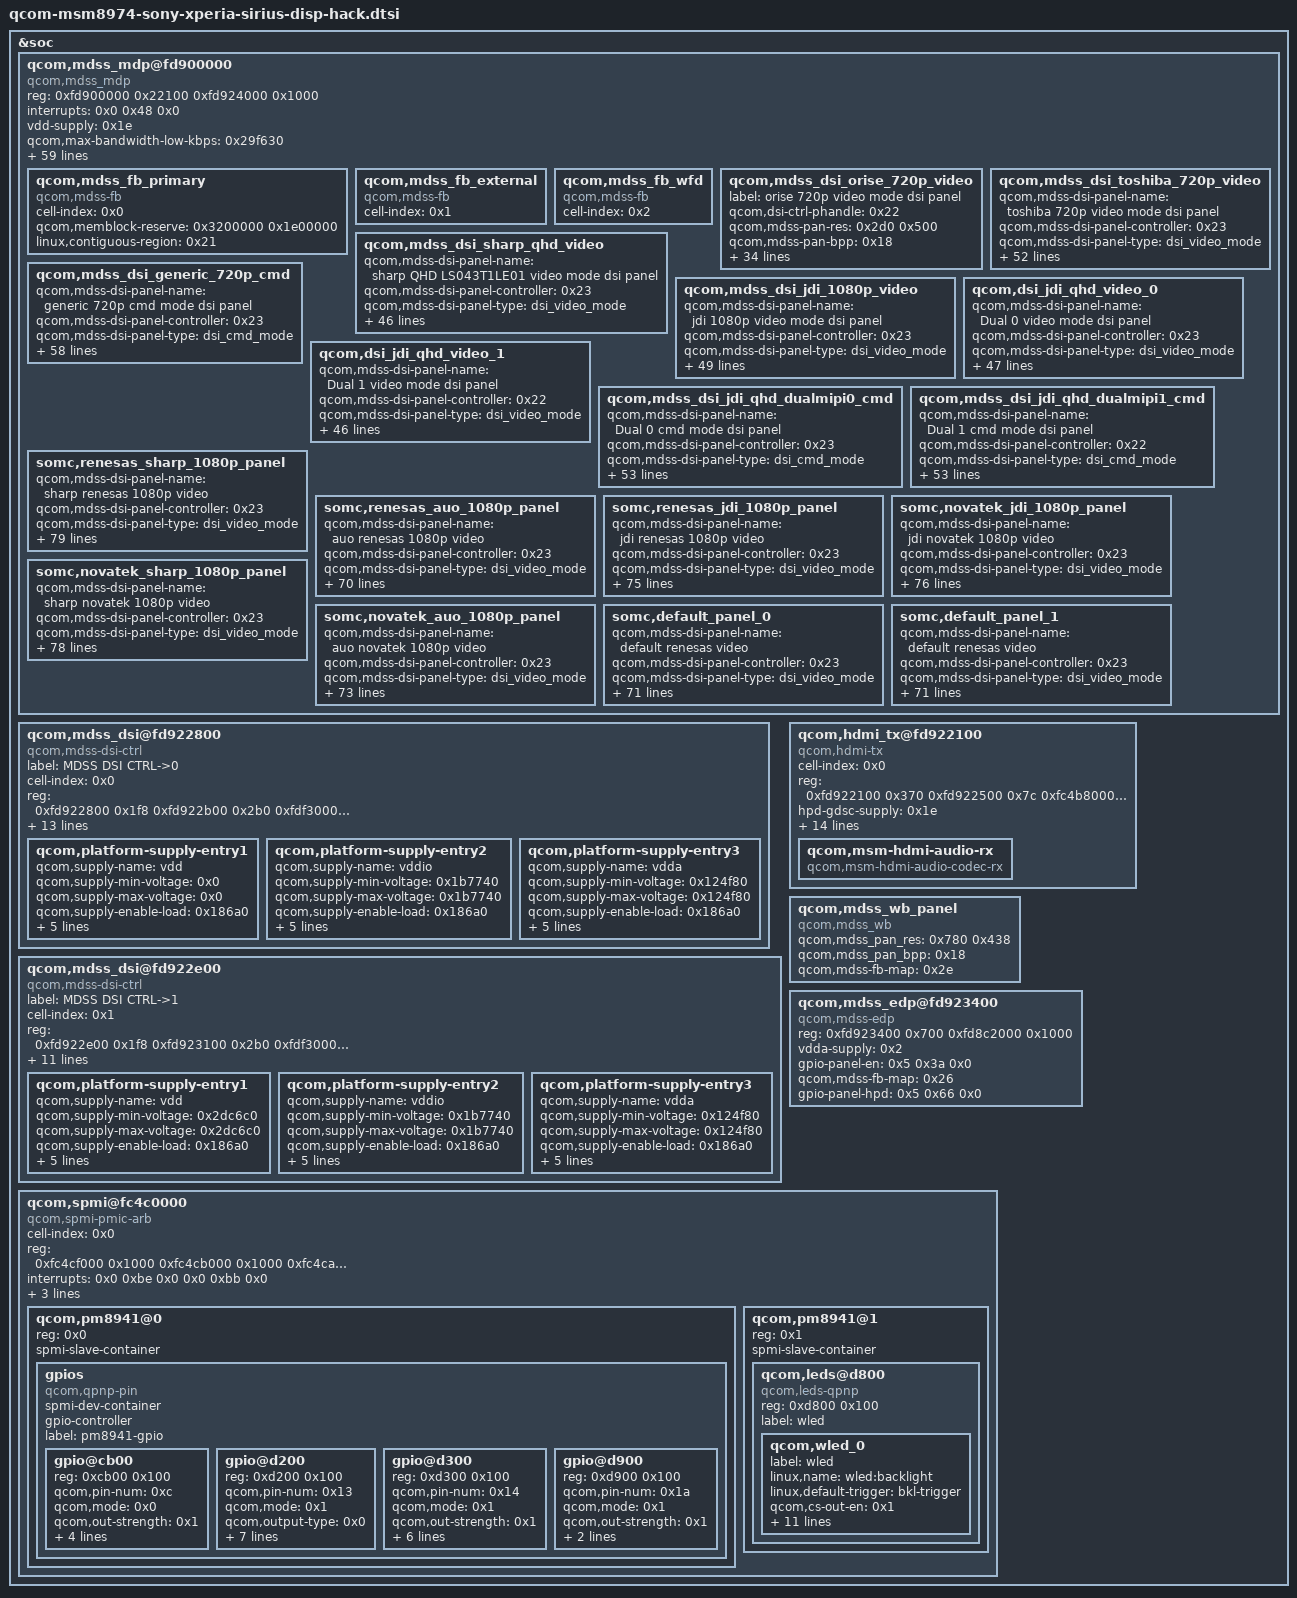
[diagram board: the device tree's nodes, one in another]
&soc {
		qcom,mdss_mdp@fd900000 {
			compatible = "qcom,mdss_mdp";
			reg = <0xfd900000 0x22100 0xfd924000 0x1000>;
			reg-names = "mdp_phys", "vbif_phys";
			interrupts = <0x0 0x48 0x0>;
			vdd-supply = <0x1e>;
			qcom,max-bandwidth-low-kbps = <0x29f630>;
			qcom,max-bandwidth-high-kbps = <0x2dc6c0>;
			qcom,msm-bus,name = "mdss_mdp";
			qcom,msm-bus,num-cases = <0x3>;
			qcom,msm-bus,num-paths = <0x1>;
			qcom,msm-bus,vectors-KBps = <0x16 0x200 0x0 0x0 0x16 0x200 0x0 0x61a800 0x16 0x200 0x0 0x61a800>;
			qcom,mdss-ab-factor = <0x2 0x1>;
			qcom,mdss-ib-factor = <0x13 0xa>;
			qcom,mdss-clk-factor = <0x5 0x4>;
			qcom,mdss-ib-factor-overlap = <0x7 0x4>;
			qcom,max-clk-rate = <0x1312d000>;
			qcom,mdss-pipe-vig-off = <0x1200 0x1600 0x1a00>;
			qcom,mdss-pipe-rgb-off = <0x1e00 0x2200 0x2600>;
			qcom,mdss-pipe-dma-off = <0x2a00 0x2e00>;
			qcom,mdss-pipe-vig-fetch-id = <0x1 0x4 0x7>;
			qcom,mdss-pipe-rgb-fetch-id = <0x10 0x11 0x12>;
			qcom,mdss-pipe-dma-fetch-id = <0xa 0xd>;
			qcom,mdss-pipe-vig-xin-id = <0x0 0x4 0x8>;
			qcom,mdss-pipe-rgb-xin-id = <0x1 0x5 0x9>;
			qcom,mdss-pipe-dma-xin-id = <0x2 0xa>;
			qcom,mdss-pipe-vig-clk-ctrl-offsets = <0x3ac 0x0 0x0 0x3b4 0x0 0x0 0x3bc 0x0 0x0>;
			qcom,mdss-pipe-rgb-clk-ctrl-offsets = <0x3ac 0x4 0x8 0x3b4 0x4 0x8 0x3bc 0x4 0x8>;
			qcom,mdss-pipe-dma-clk-ctrl-offsets = <0x3ac 0x8 0xc 0x3b4 0x8 0xc>;
			qcom,mdss-smp-data = <0x16 0x1000>;
			qcom,mdss-ctl-off = <0x600 0x700 0x800 0x900 0xa00>;
			qcom,mdss-mixer-intf-off = <0x3200 0x3600 0x3a00>;
			qcom,mdss-mixer-wb-off = <0x3e00 0x4200>;
			qcom,mdss-dspp-off = <0x4600 0x4a00 0x4e00>;
			qcom,mdss-wb-off = <0x11100 0x11500 0x11900 0x11d00 0x12100>;
			qcom,mdss-intf-off = <0x12500 0x12700 0x12900 0x12b00>;
			qcom,mdss-has-wfd-blk;
			qcom,vbif-settings = <0x4 0x1>;
			qcom,mdp-settings = <0x2e0 0xe9 0x2e4 0x55 0x3ac 0xc0000ccc 0x3b4 0xc0000ccc 0x3bc 0xcccccc 0x4a8 0xcccc0c0 0x4b0 0xccccc0c0 0x4b8 0xccccc000>;
			qcom,mdss-prefill-outstanding-buffer-bytes = <0x400>;
			qcom,mdss-prefill-y-buffer-bytes = <0x1000>;
			qcom,mdss-prefill-scaler-buffer-lines-bilinear = <0x2>;
			qcom,mdss-prefill-scaler-buffer-lines-caf = <0x4>;
			qcom,mdss-prefill-post-scaler-buffer-pixels = <0x0>;
			qcom,mdss-prefill-pingpong-buffer-pixels = <0x1000>;
			qcom,mdss-prefill-fbc-lines = <0x2>;
			qcom,mdss-pingpong-off = <0x12d00 0x12e00 0x12f00>;
			qcom,mdss-has-bwc;
			qcom,mdss-has-decimation;
			qcom,mdss-ad-off = <0x13100 0x13300>;
			vdd-cx-supply = <0x1f>;
			qcom,mdss-pref-prim-intf = "dsi";
			batfet-supply = <0x20>;
			linux,phandle = <0x27>;
			phandle = <0x27>;

			qcom,mdss_fb_primary {
				cell-index = <0x0>;
				compatible = "qcom,mdss-fb";
				qcom,memblock-reserve = <0x3200000 0x1e00000>;
				linux,contiguous-region = <0x21>;
				linux,phandle = <0x26>;
				phandle = <0x26>;
			};

			qcom,mdss_fb_external {
				cell-index = <0x1>;
				compatible = "qcom,mdss-fb";
				linux,phandle = <0x2d>;
				phandle = <0x2d>;
			};

			qcom,mdss_fb_wfd {
				cell-index = <0x2>;
				compatible = "qcom,mdss-fb";
				linux,phandle = <0x2e>;
				phandle = <0x2e>;
			};

			qcom,mdss_dsi_orise_720p_video {
				label = "orise 720p video mode dsi panel";
				qcom,dsi-ctrl-phandle = <0x22>;
				qcom,mdss-pan-res = <0x2d0 0x500>;
				qcom,mdss-pan-bpp = <0x18>;
				qcom,mdss-pan-dest = "display_2";
				qcom,mdss-pan-porch-values = <0x20 0xc 0x90 0x3 0x4 0x9>;
				qcom,mdss-pan-underflow-clr = <0xff>;
				qcom,mdss-pan-bl-levels = <0x1 0xff>;
				qcom,mdss-pan-dsi-mode = <0x0>;
				qcom,mdss-pan-dsi-h-pulse-mode = <0x0>;
				qcom,mdss-pan-dsi-h-power-stop = <0x0 0x0 0x0>;
				qcom,mdss-pan-dsi-bllp-power-stop = <0x1 0x1>;
				qcom,mdss-pan-dsi-traffic-mode = <0x1>;
				qcom,mdss-pan-dsi-dst-format = <0x3>;
				qcom,mdss-pan-dsi-vc = <0x0>;
				qcom,mdss-pan-dsi-rgb-swap = <0x0>;
				qcom,mdss-pan-dsi-data-lanes = <0x1 0x1 0x1 0x1>;
				qcom,mdss-pan-dsi-dlane-swap = <0x0>;
				qcom,mdss-pan-dsi-t-clk = <0x1b 0x4>;
				qcom,mdss-pan-dsi-stream = <0x0>;
				qcom,mdss-pan-dsi-mdp-tr = <0x0>;
				qcom,mdss-pan-dsi-dma-tr = <0x4>;
				qcom,mdss-pan-dsi-framerate = <0x3c>;
				qcom,panel-phy-regulatorSettings = [03 01 01 00 20 00 01];
				qcom,panel-phy-timingSettings = <0x69291f00 0x5555192a 0x2a030400>;
				qcom,panel-phy-strengthCtrl = [77 06];
				qcom,panel-phy-bistCtrl = [00 00 b1 ff 00 00];
				qcom,panel-phy-laneConfig = [00 c2 45 00 00 00 00 01 75 00 c2 45 00 00 00 00 01 75 00 c2 45 00 00 00 00 01 75 00 c2 45 00 00 00 00 01 75 00 02 45 00 00 00 00 01 97];
				qcom,panel-on-cmds = [05 01 00 00 78 00 02 11 00 05 01 00 00 78 00 02 29 00];
				qcom,on-cmds-dsi-state = "DSI_LP_MODE";
				qcom,panel-off-cmds = [05 01 00 00 32 00 02 28 00 05 01 00 00 78 00 02 10 00];
				qcom,off-cmds-dsi-state = "DSI_LP_MODE";
			};

			qcom,mdss_dsi_toshiba_720p_video {
				qcom,mdss-dsi-panel-name = "toshiba 720p video mode dsi panel";
				qcom,mdss-dsi-panel-controller = <0x23>;
				qcom,mdss-dsi-panel-type = "dsi_video_mode";
				qcom,mdss-dsi-panel-destination = "display_1";
				qcom,mdss-dsi-panel-framerate = <0x3c>;
				qcom,mdss-dsi-virtual-channel-id = <0x0>;
				qcom,mdss-dsi-stream = <0x0>;
				qcom,mdss-dsi-panel-width = <0x2d0>;
				qcom,mdss-dsi-panel-height = <0x500>;
				qcom,mdss-dsi-h-front-porch = <0x90>;
				qcom,mdss-dsi-h-back-porch = <0x20>;
				qcom,mdss-dsi-h-pulse-width = <0xc>;
				qcom,mdss-dsi-h-sync-skew = <0x0>;
				qcom,mdss-dsi-v-back-porch = <0x3>;
				qcom,mdss-dsi-v-front-porch = <0x9>;
				qcom,mdss-dsi-v-pulse-width = <0x4>;
				qcom,mdss-dsi-h-left-border = <0x0>;
				qcom,mdss-dsi-h-right-border = <0x0>;
				qcom,mdss-dsi-v-top-border = <0x0>;
				qcom,mdss-dsi-v-bottom-border = <0x0>;
				qcom,mdss-dsi-bpp = <0x18>;
				qcom,mdss-dsi-underflow-color = <0xff>;
				qcom,mdss-dsi-border-color = <0x0>;
				qcom,mdss-dsi-on-command = [23 01 00 00 0a 00 02 b0 00 23 01 00 00 0a 00 02 b2 00 23 01 00 00 0a 00 02 b3 0c 23 01 00 00 0a 00 02 b4 02 29 01 00 00 00 00 06 c0 40 02 7f c8 08 29 01 00 00 00 00 10 c1 00 a8 00 00 00 00 00 9d 08 27 00 00 00 00 00 29 01 00 00 00 00 06 c2 00 00 09 00 00 23 01 00 00 0a 00 02 c3 04 29 01 00 00 00 00 04 c4 4d 83 00 29 01 00 00 00 00 0b c6 12 00 08 71 00 00 00 80 00 04 23 01 00 00 0a 00 02 c7 22 29 01 00 00 00 00 05 c8 4c 0c 0c 0c 29 01 00 00 00 00 0e c9 00 40 00 16 32 2e 3a 43 3e 3c 45 79 3f 29 01 00 00 00 00 0e ca 00 46 1a 23 21 1c 25 31 2d 49 5f 7f 3f 29 01 00 00 00 00 0e cb 00 4c 20 3a 42 40 47 4b 42 3e 46 7e 3f 29 01 00 00 00 00 0e cc 00 41 19 21 1d 14 18 1f 1d 25 3f 73 3f 29 01 00 00 00 00 0e cd 23 79 5a 5f 57 4c 51 51 45 3f 4b 7f 3f 29 01 00 00 00 00 0e ce 00 40 14 20 1a 0e 0e 13 08 00 05 46 1c 29 01 00 00 00 00 04 d0 6a 64 01 29 01 00 00 00 00 03 d1 77 d4 23 01 00 00 0a 00 02 d3 33 29 01 00 00 00 00 03 d5 0f 0f 29 01 00 00 00 00 07 d8 34 64 23 25 62 32 29 01 00 00 00 00 0c de 10 7b 11 0a 00 00 00 00 00 00 00 29 01 00 00 00 00 09 fd 04 55 53 00 70 ff 10 73 23 01 00 00 0a 00 02 e2 00 05 01 00 00 78 00 02 11 00 05 01 00 00 32 00 02 29 00];
				qcom,mdss-dsi-off-command = [05 01 00 00 32 00 02 28 00 05 01 00 00 78 00 02 10 00];
				qcom,mdss-dsi-on-command-state = "dsi_lp_mode";
				qcom,mdss-dsi-off-command-state = "dsi_hs_mode";
				qcom,mdss-dsi-h-sync-pulse = <0x0>;
				qcom,mdss-dsi-traffic-mode = "non_burst_sync_event";
				qcom,mdss-dsi-bllp-eof-power-mode;
				qcom,mdss-dsi-bllp-power-mode;
				qcom,mdss-dsi-lane-0-state;
				qcom,mdss-dsi-lane-1-state;
				qcom,mdss-dsi-lane-2-state;
				qcom,mdss-dsi-lane-3-state;
				qcom,mdss-dsi-panel-timings = <0xb0231b00 0x94931e25 0x15030400>;
				qcom,mdss-dsi-t-clk-post = <0x4>;
				qcom,mdss-dsi-t-clk-pre = <0x1b>;
				qcom,mdss-dsi-bl-min-level = <0x1>;
				qcom,mdss-dsi-bl-max-level = <0xfff>;
				qcom,mdss-dsi-dma-trigger = "trigger_sw";
				qcom,mdss-dsi-mdp-trigger = "none";
				qcom,mdss-dsi-bl-pmic-control-type = "bl_ctrl_wled";
				qcom,mdss-dsi-pan-enable-dynamic-fps;
				qcom,mdss-dsi-pan-fps-update = "dfps_immediate_porch_mode";
				qcom,mdss-dsi-min-refresh-rate = <0x2d>;
				qcom,mdss-dsi-reset-sequence = <0x1 0x14 0x0 0xc8 0x1 0x14>;
				qcom,cont-splash-enabled;
			};

			qcom,mdss_dsi_sharp_qhd_video {
				qcom,mdss-dsi-panel-name = "sharp QHD LS043T1LE01 video mode dsi panel";
				qcom,mdss-dsi-panel-controller = <0x23>;
				qcom,mdss-dsi-panel-type = "dsi_video_mode";
				qcom,mdss-dsi-panel-destination = "display_1";
				qcom,mdss-dsi-panel-framerate = <0x3c>;
				qcom,mdss-dsi-virtual-channel-id = <0x0>;
				qcom,mdss-dsi-stream = <0x0>;
				qcom,mdss-dsi-panel-width = <0x21c>;
				qcom,mdss-dsi-panel-height = <0x3c0>;
				qcom,mdss-dsi-h-front-porch = <0x30>;
				qcom,mdss-dsi-h-back-porch = <0x50>;
				qcom,mdss-dsi-h-pulse-width = <0x20>;
				qcom,mdss-dsi-h-sync-skew = <0x0>;
				qcom,mdss-dsi-v-back-porch = <0xf>;
				qcom,mdss-dsi-v-front-porch = <0x3>;
				qcom,mdss-dsi-v-pulse-width = <0xa>;
				qcom,mdss-dsi-h-left-border = <0x0>;
				qcom,mdss-dsi-h-right-border = <0x0>;
				qcom,mdss-dsi-v-top-border = <0x0>;
				qcom,mdss-dsi-v-bottom-border = <0x0>;
				qcom,mdss-dsi-bpp = <0x18>;
				qcom,mdss-dsi-color-order = "rgb_swap_bgr";
				qcom,mdss-dsi-underflow-color = <0xff>;
				qcom,mdss-dsi-border-color = <0x0>;
				qcom,mdss-dsi-on-command = [05 01 00 00 32 00 02 01 00 05 01 00 00 0a 00 02 11 00 15 01 00 00 0a 00 02 53 2c 15 01 00 00 0a 00 02 51 ff 05 01 00 00 0a 00 02 29 00 15 01 00 00 0a 00 02 ae 03 15 01 00 00 0a 00 02 3a 77];
				qcom,mdss-dsi-off-command = [05 01 00 00 0a 00 02 28 00 05 01 00 00 78 00 02 10 00];
				qcom,mdss-dsi-on-command-state = "dsi_lp_mode";
				qcom,mdss-dsi-off-command-state = "dsi_hs_mode";
				qcom,mdss-dsi-h-sync-pulse = <0x1>;
				qcom,mdss-dsi-traffic-mode = "non_burst_sync_pulse";
				qcom,mdss-dsi-bllp-eof-power-mode;
				qcom,mdss-dsi-bllp-power-mode;
				qcom,mdss-dsi-lane-0-state;
				qcom,mdss-dsi-lane-1-state;
				qcom,mdss-dsi-panel-timings = <0x461d2000 0x393a2121 0x32030400>;
				qcom,mdss-dsi-t-clk-post = <0x4>;
				qcom,mdss-dsi-t-clk-pre = <0x1c>;
				qcom,mdss-dsi-bl-min-level = <0x1>;
				qcom,mdss-dsi-bl-max-level = <0xfff>;
				qcom,mdss-dsi-dma-trigger = "trigger_sw";
				qcom,mdss-dsi-mdp-trigger = "trigger_sw";
				qcom,mdss-dsi-bl-pmic-control-type = "bl_ctrl_wled";
				qcom,mdss-dsi-reset-sequence = <0x1 0x14 0x0 0xc8 0x1 0x14>;
			};

			qcom,mdss_dsi_generic_720p_cmd {
				qcom,mdss-dsi-panel-name = "generic 720p cmd mode dsi panel";
				qcom,mdss-dsi-panel-controller = <0x23>;
				qcom,mdss-dsi-panel-type = "dsi_cmd_mode";
				qcom,mdss-dsi-panel-destination = "display_1";
				qcom,mdss-dsi-panel-framerate = <0x3c>;
				qcom,mdss-dsi-stream = <0x0>;
				qcom,mdss-dsi-panel-width = <0x300>;
				qcom,mdss-dsi-panel-height = <0x500>;
				qcom,mdss-dsi-h-front-porch = <0x1a>;
				qcom,mdss-dsi-h-back-porch = <0x1a>;
				qcom,mdss-dsi-h-pulse-width = <0x1a>;
				qcom,mdss-dsi-h-sync-skew = <0x0>;
				qcom,mdss-dsi-v-back-porch = <0x2>;
				qcom,mdss-dsi-v-front-porch = <0x2>;
				qcom,mdss-dsi-v-pulse-width = <0x2>;
				qcom,mdss-dsi-h-left-border = <0x0>;
				qcom,mdss-dsi-h-right-border = <0x0>;
				qcom,mdss-dsi-v-top-border = <0x0>;
				qcom,mdss-dsi-v-bottom-border = <0x0>;
				qcom,mdss-dsi-bpp = <0x18>;
				qcom,mdss-dsi-underflow-color = <0xff>;
				qcom,mdss-dsi-border-color = <0x0>;
				qcom,mdss-dsi-on-command = [05 01 00 00 78 00 01 11 15 01 00 00 0a 00 02 36 00 05 01 00 00 0a 00 01 29 15 01 00 00 0a 00 02 53 24 15 01 00 00 0a 00 02 35 00];
				qcom,mdss-dsi-off-command = [05 01 00 00 0a 00 01 34 05 01 00 00 78 00 01 10 05 01 00 00 78 00 01 28 15 01 00 00 0a 00 02 53 00];
				qcom,mdss-dsi-on-command-state = "dsi_lp_mode";
				qcom,mdss-dsi-off-command-state = "dsi_hs_mode";
				qcom,mdss-dsi-h-sync-pulse = <0x0>;
				qcom,mdss-dsi-traffic-mode = "non_burst_sync_event";
				qcom,mdss-dsi-bllp-eof-power-mode;
				qcom,mdss-dsi-bllp-power-mode;
				qcom,mdss-dsi-lane-0-state;
				qcom,mdss-dsi-lane-1-state;
				qcom,mdss-dsi-lane-2-state;
				qcom,mdss-dsi-lane-3-state;
				qcom,mdss-dsi-te-pin-select = <0x1>;
				qcom,mdss-dsi-wr-mem-start = <0x2c>;
				qcom,mdss-dsi-wr-mem-continue = <0x3c>;
				qcom,mdss-dsi-te-dcs-command = <0x1>;
				qcom,mdss-dsi-te-check-enable;
				qcom,mdss-dsi-te-using-te-pin;
				qcom,mdss-dsi-panel-timings = <0x6e261b00 0x35342028 0x17030400>;
				qcom,mdss-dsi-t-clk-post = <0x20>;
				qcom,mdss-dsi-t-clk-pre = <0x2a>;
				qcom,mdss-dsi-bl-min-level = <0x1>;
				qcom,mdss-dsi-bl-max-level = <0xff>;
				qcom,mdss-dsi-bl-pmic-pwm-frequency = <0x64>;
				qcom,mdss-dsi-bl-pmic-bank-select = <0x7>;
				qcom,mdss-dsi-dma-trigger = "trigger_sw";
				qcom,mdss-dsi-mdp-trigger = "none";
				qcom,mdss-dsi-bl-pmic-control-type = "bl_ctrl_pwm";
				qcom,mdss-dsi-reset-sequence = <0x1 0x14 0x0 0xc8 0x1 0x14>;
				qcom,panel-roi-alignment = <0x2 0x2 0x2 0x2 0x0 0x0>;
				qcom,partial-update-enabled;
				qcom,cont-splash-enabled;
			};

			qcom,mdss_dsi_jdi_1080p_video {
				qcom,mdss-dsi-panel-name = "jdi 1080p video mode dsi panel";
				qcom,mdss-dsi-panel-controller = <0x23>;
				qcom,mdss-dsi-panel-type = "dsi_video_mode";
				qcom,mdss-dsi-panel-destination = "display_1";
				qcom,mdss-dsi-panel-framerate = <0x3c>;
				qcom,mdss-dsi-virtual-channel-id = <0x0>;
				qcom,mdss-dsi-stream = <0x0>;
				qcom,mdss-dsi-panel-width = <0x438>;
				qcom,mdss-dsi-panel-height = <0x780>;
				qcom,mdss-dsi-h-front-porch = <0x60>;
				qcom,mdss-dsi-h-back-porch = <0x40>;
				qcom,mdss-dsi-h-pulse-width = <0x10>;
				qcom,mdss-dsi-h-sync-skew = <0x0>;
				qcom,mdss-dsi-v-back-porch = <0x10>;
				qcom,mdss-dsi-v-front-porch = <0x4>;
				qcom,mdss-dsi-v-pulse-width = <0x1>;
				qcom,mdss-dsi-h-left-border = <0x0>;
				qcom,mdss-dsi-h-right-border = <0x0>;
				qcom,mdss-dsi-v-top-border = <0x0>;
				qcom,mdss-dsi-v-bottom-border = <0x0>;
				qcom,mdss-dsi-bpp = <0x18>;
				qcom,mdss-dsi-underflow-color = <0xff>;
				qcom,mdss-dsi-border-color = <0x0>;
				qcom,mdss-dsi-on-command = [15 01 00 00 00 00 02 55 00 15 01 00 00 00 00 02 53 2c 15 01 00 00 00 00 02 35 00 05 01 00 00 78 00 02 29 00 05 01 00 00 78 00 02 11 00];
				qcom,mdss-dsi-off-command = [05 01 00 00 02 00 02 28 00 05 01 00 00 79 00 02 10 00];
				qcom,mdss-dsi-on-command-state = "dsi_lp_mode";
				qcom,mdss-dsi-off-command-state = "dsi_hs_mode";
				qcom,mdss-dsi-h-sync-pulse = <0x0>;
				qcom,mdss-dsi-traffic-mode = "burst_mode";
				qcom,mdss-dsi-bllp-eof-power-mode;
				qcom,mdss-dsi-bllp-power-mode;
				qcom,mdss-dsi-lane-0-state;
				qcom,mdss-dsi-lane-1-state;
				qcom,mdss-dsi-lane-2-state;
				qcom,mdss-dsi-lane-3-state;
				qcom,mdss-dsi-panel-timings = <0xe7362400 0x666a2a3a 0x2d030400>;
				qcom,mdss-dsi-t-clk-post = <0x4>;
				qcom,mdss-dsi-t-clk-pre = <0x1b>;
				qcom,mdss-dsi-bl-min-level = <0x1>;
				qcom,mdss-dsi-bl-max-level = <0xfff>;
				qcom,mdss-dsi-dma-trigger = "trigger_sw";
				qcom,mdss-dsi-mdp-trigger = "none";
				qcom,mdss-dsi-bl-pmic-control-type = "bl_ctrl_wled";
				qcom,mdss-dsi-reset-sequence = <0x1 0x14 0x0 0xc8 0x1 0x14>;
				qcom,mdss-pan-physical-width-dimension = <0x3d>;
				qcom,mdss-pan-physical-height-dimension = <0x6e>;
				qcom,cont-splash-enabled;
			};

			qcom,dsi_jdi_qhd_video_0 {
				qcom,mdss-dsi-panel-name = "Dual 0 video mode dsi panel";
				qcom,mdss-dsi-panel-controller = <0x23>;
				qcom,mdss-dsi-panel-type = "dsi_video_mode";
				qcom,mdss-dsi-panel-destination = "display_1";
				qcom,mdss-dsi-panel-framerate = <0x3c>;
				qcom,mdss-dsi-virtual-channel-id = <0x0>;
				qcom,mdss-dsi-stream = <0x0>;
				qcom,mdss-dsi-panel-width = <0x500>;
				qcom,mdss-dsi-panel-height = <0x5a0>;
				qcom,mdss-dsi-h-front-porch = <0x78>;
				qcom,mdss-dsi-h-back-porch = <0x2c>;
				qcom,mdss-dsi-h-pulse-width = <0x10>;
				qcom,mdss-dsi-h-sync-skew = <0x0>;
				qcom,mdss-dsi-v-back-porch = <0x4>;
				qcom,mdss-dsi-v-front-porch = <0x8>;
				qcom,mdss-dsi-v-pulse-width = <0x4>;
				qcom,mdss-dsi-h-left-border = <0x0>;
				qcom,mdss-dsi-h-right-border = <0x0>;
				qcom,mdss-dsi-v-top-border = <0x0>;
				qcom,mdss-dsi-v-bottom-border = <0x0>;
				qcom,mdss-dsi-bpp = <0x18>;
				qcom,mdss-dsi-underflow-color = <0xff>;
				qcom,mdss-dsi-border-color = <0x0>;
				qcom,mdss-dsi-h-sync-pulse = <0x0>;
				qcom,mdss-dsi-traffic-mode = "non_burst_sync_event";
				qcom,mdss-dsi-bllp-eof-power-mode;
				qcom,mdss-dsi-bllp-power-mode;
				qcom,mdss-dsi-panel-broadcast-mode;
				qcom,mdss-dsi-lane-0-state;
				qcom,mdss-dsi-lane-1-state;
				qcom,mdss-dsi-lane-2-state;
				qcom,mdss-dsi-lane-3-state;
				qcom,mdss-dsi-panel-timings = <0xcd322200 0x60642634 0x29030400>;
				qcom,mdss-dsi-t-clk-post = <0x3>;
				qcom,mdss-dsi-t-clk-pre = <0x27>;
				qcom,mdss-dsi-bl-max-level = <0xfff>;
				qcom,mdss-dsi-dma-trigger = "trigger_sw";
				qcom,mdss-dsi-mdp-trigger = "none";
				qcom,mdss-dsi-bl-pmic-control-type = "bl_ctrl_pwm";
				qcom,mdss-dsi-on-command = [05 01 00 00 0a 00 01 00 15 01 00 00 0a 00 02 3a 77 39 01 00 00 0a 00 05 2a 00 00 04 ff 39 01 00 00 0a 00 05 2b 00 00 05 9f 15 01 00 00 0a 00 02 35 00 39 01 00 00 0a 00 03 44 00 00 15 01 00 00 0a 00 02 51 ff 15 01 00 00 0a 00 02 53 24 15 01 00 00 0a 00 02 55 00 05 01 00 00 78 00 01 11 23 01 00 00 0a 00 02 b0 00 29 01 00 00 0a 00 02 b3 14 29 01 00 00 0a 00 14 ce 7d 40 48 56 67 78 88 98 a7 b5 c3 d1 de e9 f2 fa ff 04 00 23 01 00 00 0a 00 02 b0 03 05 01 00 00 10 00 01 29];
				qcom,mdss-dsi-on-command-state = "dsi_lp_mode";
				qcom,mdss-dsi-off-command = [05 01 00 00 32 00 02 28 00 05 01 00 00 78 00 02 10 00];
				qcom,mdss-dsi-off-command-state = "dsi_hs_mode";
				qcom,mdss-dsi-reset-sequence = <0x1 0x14 0x0 0xc8 0x1 0x14>;
			};

			qcom,dsi_jdi_qhd_video_1 {
				qcom,mdss-dsi-panel-name = "Dual 1 video mode dsi panel";
				qcom,mdss-dsi-panel-controller = <0x22>;
				qcom,mdss-dsi-panel-type = "dsi_video_mode";
				qcom,mdss-dsi-panel-destination = "display_2";
				qcom,mdss-dsi-panel-framerate = <0x3c>;
				qcom,mdss-dsi-virtual-channel-id = <0x0>;
				qcom,mdss-dsi-stream = <0x0>;
				qcom,mdss-dsi-panel-width = <0x500>;
				qcom,mdss-dsi-panel-height = <0x5a0>;
				qcom,mdss-dsi-h-front-porch = <0x78>;
				qcom,mdss-dsi-h-back-porch = <0x2c>;
				qcom,mdss-dsi-h-pulse-width = <0x10>;
				qcom,mdss-dsi-h-sync-skew = <0x0>;
				qcom,mdss-dsi-v-back-porch = <0x4>;
				qcom,mdss-dsi-v-front-porch = <0x8>;
				qcom,mdss-dsi-v-pulse-width = <0x4>;
				qcom,mdss-dsi-h-left-border = <0x0>;
				qcom,mdss-dsi-h-right-border = <0x0>;
				qcom,mdss-dsi-v-top-border = <0x0>;
				qcom,mdss-dsi-v-bottom-border = <0x0>;
				qcom,mdss-dsi-bpp = <0x18>;
				qcom,mdss-dsi-underflow-color = <0xff>;
				qcom,mdss-dsi-border-color = <0x0>;
				qcom,mdss-dsi-h-sync-pulse = <0x0>;
				qcom,mdss-dsi-traffic-mode = "non_burst_sync_event";
				qcom,mdss-dsi-bllp-eof-power-mode;
				qcom,mdss-dsi-bllp-power-mode;
				qcom,mdss-dsi-lane-0-state;
				qcom,mdss-dsi-lane-1-state;
				qcom,mdss-dsi-lane-2-state;
				qcom,mdss-dsi-lane-3-state;
				qcom,mdss-dsi-panel-broadcast-mode;
				qcom,mdss-dsi-panel-timings = <0xcd322200 0x60642634 0x29030400>;
				qcom,mdss-dsi-t-clk-post = <0x3>;
				qcom,mdss-dsi-t-clk-pre = <0x27>;
				qcom,mdss-dsi-bl-min-level = <0x1>;
				qcom,mdss-dsi-bl-max-level = <0xfff>;
				qcom,mdss-dsi-dma-trigger = "trigger_sw";
				qcom,mdss-dsi-mdp-trigger = "none";
				qcom,mdss-dsi-on-command = [05 01 00 00 0a 00 01 00 15 01 00 00 0a 00 02 3a 77 39 01 00 00 0a 00 05 2a 00 00 04 ff 39 01 00 00 0a 00 05 2b 00 00 05 9f 15 01 00 00 0a 00 02 35 00 39 01 00 00 0a 00 03 44 00 00 15 01 00 00 0a 00 02 51 ff 15 01 00 00 0a 00 02 53 24 15 01 00 00 0a 00 02 55 00 05 01 00 00 78 00 01 11 23 01 00 00 0a 00 02 b0 00 29 01 00 00 0a 00 02 b3 14 29 01 00 00 0a 00 14 ce 7d 40 48 56 67 78 88 98 a7 b5 c3 d1 de e9 f2 fa ff 04 00 23 01 00 00 0a 00 02 b0 03 05 01 00 00 10 00 01 29];
				qcom,mdss-dsi-on-command-state = "dsi_lp_mode";
				qcom,mdss-dsi-off-command = [05 01 00 00 32 00 02 28 00 05 01 00 00 78 00 02 10 00];
				qcom,mdss-dsi-off-command-state = "dsi_hs_mode";
				qcom,mdss-dsi-reset-sequence = <0x1 0x14 0x0 0xc8 0x1 0x14>;
			};

			qcom,mdss_dsi_jdi_qhd_dualmipi0_cmd {
				qcom,mdss-dsi-panel-name = "Dual 0 cmd mode dsi panel";
				qcom,mdss-dsi-panel-controller = <0x23>;
				qcom,mdss-dsi-panel-type = "dsi_cmd_mode";
				qcom,mdss-dsi-panel-destination = "display_1";
				qcom,mdss-dsi-panel-framerate = <0x3c>;
				qcom,mdss-dsi-virtual-channel-id = <0x0>;
				qcom,mdss-dsi-stream = <0x0>;
				qcom,mdss-dsi-panel-width = <0x500>;
				qcom,mdss-dsi-panel-height = <0x5a0>;
				qcom,mdss-dsi-h-front-porch = <0x78>;
				qcom,mdss-dsi-h-back-porch = <0x2c>;
				qcom,mdss-dsi-h-pulse-width = <0x10>;
				qcom,mdss-dsi-h-sync-skew = <0x0>;
				qcom,mdss-dsi-v-back-porch = <0x4>;
				qcom,mdss-dsi-v-front-porch = <0x8>;
				qcom,mdss-dsi-v-pulse-width = <0x4>;
				qcom,mdss-dsi-h-left-border = <0x0>;
				qcom,mdss-dsi-h-right-border = <0x0>;
				qcom,mdss-dsi-v-top-border = <0x0>;
				qcom,mdss-dsi-v-bottom-border = <0x0>;
				qcom,mdss-dsi-bpp = <0x18>;
				qcom,mdss-dsi-color-order = "rgb_swap_rgb";
				qcom,mdss-dsi-underflow-color = <0xff>;
				qcom,mdss-dsi-border-color = <0x0>;
				qcom,mdss-dsi-h-sync-pulse = <0x0>;
				qcom,mdss-dsi-traffic-mode = "non_burst_sync_event";
				qcom,mdss-dsi-lane-map = "lane_map_0123";
				qcom,mdss-dsi-bllp-eof-power-mode;
				qcom,mdss-dsi-bllp-power-mode;
				qcom,mdss-dsi-panel-broadcast-mode;
				qcom,mdss-dsi-lane-0-state;
				qcom,mdss-dsi-lane-1-state;
				qcom,mdss-dsi-lane-2-state;
				qcom,mdss-dsi-lane-3-state;
				qcom,mdss-dsi-panel-timings = <0xcd322200 0x60642634 0x29030400>;
				qcom,mdss-dsi-reset-sequence = <0x1 0xc8 0x0 0xc8 0x1 0x14>;
				qcom,mdss-dsi-t-clk-post = <0x3>;
				qcom,mdss-dsi-t-clk-pre = <0x27>;
				qcom,mdss-dsi-bl-max-level = <0xfff>;
				qcom,mdss-dsi-dma-trigger = "trigger_sw";
				qcom,mdss-dsi-mdp-trigger = "none";
				qcom,mdss-dsi-te-pin-select = <0x1>;
				qcom,mdss-dsi-te-v-sync-rd-ptr-irq-line = <0x2c>;
				qcom,mdss-dsi-te-v-sync-continues-lines = <0x3c>;
				qcom,mdss-dsi-te-dcs-command = <0x1>;
				qcom,mdss-dsi-te-check-enable;
				qcom,mdss-dsi-te-using-te-pin;
				qcom,mdss-dsi-on-command = <0x29010000 0x2b0 0x3050100 0xa0001 0x150100 0xa0002 0x3a773901 0xa00 0x52a0000 0x4ff3901 0xa00 0x52b0000 0x59f1501 0xa00 0x2350039 0x100000a 0x34400 0x150100 0xa0002 0x51ff1501 0xa00 0x2532415 0x100000a 0x25500 0x5010000 0x78000111 0x5010000 0x10000129>;
				qcom,mdss-dsi-on-command-state = "dsi_lp_mode";
				qcom,mdss-dsi-off-command = [05 01 00 00 32 00 02 28 00 05 01 00 00 78 00 02 10 00];
				qcom,mdss-dsi-off-command-state = "dsi_hs_mode";
			};

			qcom,mdss_dsi_jdi_qhd_dualmipi1_cmd {
				qcom,mdss-dsi-panel-name = "Dual 1 cmd mode dsi panel";
				qcom,mdss-dsi-panel-controller = <0x22>;
				qcom,mdss-dsi-panel-type = "dsi_cmd_mode";
				qcom,mdss-dsi-panel-destination = "display_2";
				qcom,mdss-dsi-panel-framerate = <0x3c>;
				qcom,mdss-dsi-virtual-channel-id = <0x0>;
				qcom,mdss-dsi-stream = <0x0>;
				qcom,mdss-dsi-panel-width = <0x500>;
				qcom,mdss-dsi-panel-height = <0x5a0>;
				qcom,mdss-dsi-h-front-porch = <0x78>;
				qcom,mdss-dsi-h-back-porch = <0x2c>;
				qcom,mdss-dsi-h-pulse-width = <0x10>;
				qcom,mdss-dsi-h-sync-skew = <0x0>;
				qcom,mdss-dsi-v-back-porch = <0x4>;
				qcom,mdss-dsi-v-front-porch = <0x8>;
				qcom,mdss-dsi-v-pulse-width = <0x4>;
				qcom,mdss-dsi-h-left-border = <0x0>;
				qcom,mdss-dsi-h-right-border = <0x0>;
				qcom,mdss-dsi-v-top-border = <0x0>;
				qcom,mdss-dsi-v-bottom-border = <0x0>;
				qcom,mdss-dsi-bpp = <0x18>;
				qcom,mdss-dsi-color-order = "rgb_swap_rgb";
				qcom,mdss-dsi-underflow-color = <0xff>;
				qcom,mdss-dsi-border-color = <0x0>;
				qcom,mdss-dsi-h-sync-pulse = <0x0>;
				qcom,mdss-dsi-traffic-mode = "non_burst_sync_event";
				qcom,mdss-dsi-lane-map = "lane_map_0123";
				qcom,mdss-dsi-bllp-eof-power-mode;
				qcom,mdss-dsi-bllp-power-mode;
				qcom,mdss-dsi-panel-broadcast-mode;
				qcom,mdss-dsi-lane-0-state;
				qcom,mdss-dsi-lane-1-state;
				qcom,mdss-dsi-lane-2-state;
				qcom,mdss-dsi-lane-3-state;
				qcom,mdss-dsi-panel-timings = <0xcd322200 0x60642634 0x29030400>;
				qcom,mdss-dsi-reset-sequence = <0x1 0xc8 0x0 0xc8 0x1 0x14>;
				qcom,mdss-dsi-t-clk-post = <0x3>;
				qcom,mdss-dsi-t-clk-pre = <0x27>;
				qcom,mdss-dsi-bl-max-level = <0xfff>;
				qcom,mdss-dsi-dma-trigger = "trigger_sw";
				qcom,mdss-dsi-mdp-trigger = "none";
				qcom,mdss-dsi-te-pin-select = <0x1>;
				qcom,mdss-dsi-te-v-sync-rd-ptr-irq-line = <0x2c>;
				qcom,mdss-dsi-te-v-sync-continues-lines = <0x3c>;
				qcom,mdss-dsi-te-dcs-command = <0x1>;
				qcom,mdss-dsi-te-check-enable;
				qcom,mdss-dsi-te-using-te-pin;
				qcom,mdss-dsi-on-command = <0x29010000 0x2b0 0x3050100 0xa0001 0x150100 0xa0002 0x3a773901 0xa00 0x52a0000 0x4ff3901 0xa00 0x52b0000 0x59f1501 0xa00 0x2350039 0x100000a 0x34400 0x150100 0xa0002 0x51ff1501 0xa00 0x2532415 0x100000a 0x25500 0x5010000 0x78000111 0x5010000 0x10000129>;
				qcom,mdss-dsi-on-command-state = "dsi_lp_mode";
				qcom,mdss-dsi-off-command = [05 01 00 00 32 00 02 28 00 05 01 00 00 78 00 02 10 00];
				qcom,mdss-dsi-off-command-state = "dsi_hs_mode";
			};

			somc,renesas_sharp_1080p_panel {
				qcom,mdss-dsi-panel-name = "sharp renesas 1080p video";
				qcom,mdss-dsi-panel-controller = <0x23>;
				qcom,mdss-dsi-panel-type = "dsi_video_mode";
				qcom,mdss-dsi-panel-destination = "display_1";
				qcom,mdss-dsi-panel-framerate = <0x3c>;
				qcom,mdss-dsi-virtual-channel-id = <0x0>;
				qcom,mdss-dsi-stream = <0x0>;
				qcom,mdss-dsi-panel-width = <0x438>;
				qcom,mdss-dsi-panel-height = <0x780>;
				qcom,mdss-dsi-h-front-porch = <0x80>;
				qcom,mdss-dsi-h-back-porch = <0x4c>;
				qcom,mdss-dsi-h-pulse-width = <0x4>;
				qcom,mdss-dsi-h-sync-skew = <0x0>;
				qcom,mdss-dsi-v-back-porch = <0x5>;
				qcom,mdss-dsi-v-front-porch = <0x2>;
				qcom,mdss-dsi-v-pulse-width = <0x2>;
				qcom,mdss-dsi-h-left-border = <0x0>;
				qcom,mdss-dsi-h-right-border = <0x0>;
				qcom,mdss-dsi-v-top-border = <0x0>;
				qcom,mdss-dsi-v-bottom-border = <0x0>;
				qcom,mdss-dsi-bpp = <0x18>;
				qcom,mdss-dsi-underflow-color = <0x0>;
				qcom,mdss-dsi-border-color = <0x0>;
				somc,mdss-dsi-init-command = [23 01 00 00 00 00 02 b0 04 23 01 00 00 00 00 02 00 00 23 01 00 00 00 00 02 00 00 29 01 00 00 00 00 08 c2 32 f7 80 07 08 00 00 23 01 00 00 00 00 02 d6 01 29 01 00 00 00 00 03 c0 0f 0f 29 01 00 00 00 00 03 ec 00 10 29 01 00 00 00 00 19 c7 05 19 22 2b 38 51 41 50 5c 64 6b 74 0f 23 2b 32 3f 52 44 55 61 69 70 77 29 01 00 00 00 00 19 c8 03 18 21 2b 38 51 42 4f 5d 65 6c 74 0d 22 2a 32 3e 52 41 54 5d 66 6d 77 29 01 00 00 00 00 19 c9 00 15 1e 28 36 50 42 50 5e 66 6d 74 0a 1f 27 2f 3d 51 41 55 5e 67 6e 77 05 01 00 00 00 00 01 11];
				qcom,mdss-dsi-on-command = <0x5010000 0x129>;
				qcom,mdss-dsi-off-command = <0x5010000 0x14000128 0x5010000 0x6e000110>;
				qcom,mdss-dsi-on-command-state = "dsi_lp_mode";
				qcom,mdss-dsi-off-command-state = "dsi_hs_mode";
				somc,mdss-dsi-cabc-early-on-command = <0x39010000 0x351 0xfff1501 0x0 0x2532415 0x1000000 0x25502>;
				somc,mdss-dsi-cabc-late-off-command = <0x39010000 0x351 0x1501 0x0 0x2550015 0x1000000 0x25320>;
				somc,mdss-dsi-cabc-enabled = <0x0>;
				qcom,mdss-dsi-h-sync-pulse = <0x1>;
				qcom,mdss-dsi-traffic-mode = "non_burst_sync_event";
				qcom,mdss-dsi-bllp-eof-power-mode;
				qcom,mdss-dsi-bllp-power-mode;
				qcom,mdss-dsi-lane-0-state;
				qcom,mdss-dsi-lane-1-state;
				qcom,mdss-dsi-lane-2-state;
				qcom,mdss-dsi-lane-3-state;
				qcom,mdss-dsi-panel-timings = <0xe6382600 0x686c2a3a 0x2c030400>;
				qcom,mdss-dsi-lp11-init;
				qcom,mdss-dsi-t-clk-post = <0x2>;
				qcom,mdss-dsi-t-clk-pre = <0x2b>;
				qcom,mdss-dsi-bl-min-level = <0x1>;
				qcom,mdss-dsi-bl-max-level = <0xff>;
				qcom,mdss-brightness-max-level = <0xff>;
				qcom,mdss-dsi-dma-trigger = "trigger_sw";
				qcom,mdss-dsi-mdp-trigger = "none";
				qcom,mdss-dsi-bl-pmic-control-type = "bl_ctrl_wled";
				qcom,mdss-dsi-pan-enable-dynamic-fps;
				qcom,mdss-dsi-pan-fps-update = "dfps_suspend_resume_mode";
				qcom,cont-splash-enabled;
				qcom,mdss-dsi-tx-eot-append;
				somc,driver-ic = <0x0>;
				somc,mul-channel-scaling = <0x3>;
				somc,mdss-phy-size-mm = <0x40 0x72>;
				somc,mdss-dsi-lane-config = [00 c2 ef 00 00 00 00 01 75 00 c2 ef 00 00 00 00 01 75 00 c2 ef 00 00 00 00 01 75 00 c2 ef 00 00 00 00 01 75 00 02 45 00 00 00 00 01 97];
				somc,mdss-dsi-disp-on-in-hs = <0x1>;
				somc,mdss-dsi-wait-time-before-on-cmd = <0x96>;
				somc,lcd-id = <0x1>;
				somc,lcd-id-adc = <0x0 0xdea8>;
				somc,disp-en-on-pre = <0x19>;
				somc,pw-on-rst-seq = <0x0 0x3c 0x1 0xa>;
				somc,disp-en-off-post = <0x32>;
				somc,pw-off-rst-b-seq = <0x0 0xa>;
				somc,mdss-dsi-pre-uv-command = [23 01 00 00 00 00 02 b0 04];
				somc,mdss-dsi-uv-command = <0x6010000 0x1da 0x6010000 0x1db>;
				somc,mdss-dsi-uv-param-type = <0x4>;
				somc,mdss-dsi-pcc-table-size = <0x49>;
				somc,mdss-dsi-pcc-table = <0x0 0x1 0x10 0x13 0x28 0x2b 0x8000 0x7400 0x8000 0x0 0x2 0x14 0x17 0x28 0x2b 0x7a80 0x7400 0x7e00 0x0 0x3 0x18 0x1b 0x28 0x2b 0x7480 0x7380 0x8000 0x0 0x4 0x1c 0x1f 0x28 0x2b 0x7280 0x7380 0x8000 0x0 0x5 0x20 0x23 0x28 0x2b 0x6e00 0x7400 0x8000 0x0 0x6 0xc 0xf 0x24 0x27 0x7f80 0x7200 0x7c00 0x0 0x7 0x10 0x13 0x24 0x27 0x8000 0x7400 0x7d80 0x0 0x8 0x14 0x17 0x24 0x27 0x7d00 0x7700 0x7e00 0x0 0x9 0x18 0x1b 0x24 0x27 0x7700 0x7600 0x8000 0x0 0xa 0x1c 0x1f 0x24 0x27 0x7380 0x7500 0x7c00 0x0 0xb 0x20 0x23 0x24 0x27 0x6f00 0x7500 0x7e80 0x0 0xc 0xc 0xf 0x20 0x23 0x7f80 0x7200 0x7900 0x0 0xd 0x10 0x13 0x20 0x23 0x8000 0x7400 0x7b00 0x0 0xe 0x14 0x17 0x20 0x23 0x7a80 0x7400 0x7b00 0x0 0xf 0x18 0x1b 0x20 0x23 0x7800 0x7700 0x7e80 0x0 0x10 0x1c 0x1f 0x20 0x23 0x7780 0x7900 0x7f80 0x0 0x11 0x20 0x23 0x20 0x23 0x7300 0x7900 0x7f00 0x0 0x12 0x24 0x27 0x20 0x23 0x7100 0x7980 0x8000 0x0 0x13 0xc 0xf 0x1c 0x1f 0x7f80 0x7200 0x7700 0x0 0x14 0x10 0x13 0x1c 0x1f 0x7c00 0x7000 0x7580 0x0 0x15 0x14 0x17 0x1c 0x1f 0x7f80 0x7900 0x7e00 0x0 0x16 0x18 0x1b 0x1c 0x1f 0x7c00 0x7a00 0x7d80 0x0 0x17 0x1c 0x1f 0x1c 0x1f 0x7900 0x7a00 0x7e00 0x0 0x18 0x20 0x23 0x1c 0x1f 0x7600 0x7c80 0x8000 0x0 0x19 0x24 0x27 0x1c 0x1f 0x7300 0x7c00 0x7e80 0x0 0x1a 0xc 0xf 0x18 0x1b 0x8000 0x7200 0x7300 0x0 0x1b 0x10 0x13 0x18 0x1b 0x7e80 0x7200 0x7500 0x0 0x1c 0x14 0x17 0x18 0x1b 0x7f00 0x7900 0x7b80 0x0 0x1d 0x18 0x1b 0x18 0x1b 0x7f00 0x7d00 0x7e00 0x0 0x1e 0x1c 0x1f 0x18 0x1b 0x7d00 0x7d80 0x8000 0x0 0x1f 0x20 0x23 0x18 0x1b 0x7900 0x7f00 0x8000 0x0 0x20 0x24 0x27 0x18 0x1b 0x7780 0x8000 0x8000 0x0 0x21 0x10 0x13 0x14 0x17 0x7f80 0x7380 0x7200 0x0 0x22 0x14 0x17 0x14 0x17 0x7f00 0x7900 0x7900 0x0 0x23 0x18 0x1b 0x14 0x17 0x7f00 0x7d00 0x7b80 0xff 0x0 0x1c 0x1f 0x14 0x17 0x8000 0x8000 0x8000 0x0 0x24 0x20 0x23 0x14 0x17 0x7a00 0x8000 0x7e80 0x0 0x25 0x24 0x27 0x14 0x17 0x7780 0x8000 0x7d80 0x0 0x26 0x10 0x13 0x10 0x13 0x8000 0x7400 0x7000 0x0 0x27 0x14 0x17 0x10 0x13 0x7f80 0x7900 0x7680 0x0 0x28 0x18 0x1b 0x10 0x13 0x8000 0x7d80 0x7980 0x0 0x29 0x1c 0x1f 0x10 0x13 0x8000 0x8000 0x7c00 0x0 0x2a 0x20 0x23 0x10 0x13 0x7a00 0x8000 0x7c00 0x0 0x2b 0x10 0x13 0xc 0xf 0x7f80 0x7480 0x6f00 0x0 0x2c 0x14 0x17 0xc 0xf 0x7f80 0x7900 0x7400 0x0 0x2d 0x18 0x1b 0xc 0xf 0x7f80 0x7d80 0x7680 0x0 0x2e 0x1c 0x1f 0xc 0xf 0x8000 0x8000 0x7980 0x1 0x0 0x0 0x9 0x32 0x3b 0x8000 0x6d00 0x8000 0x2 0x0 0xa 0x13 0x32 0x3b 0x7a00 0x7100 0x8000 0x3 0x0 0x14 0x1d 0x32 0x3b 0x7400 0x7180 0x8000 0x4 0x0 0x1e 0x27 0x32 0x3b 0x7100 0x7200 0x8000 0x5 0x0 0x28 0x31 0x32 0x3b 0x6c80 0x7180 0x8000 0x6 0x0 0x32 0x3b 0x32 0x3b 0x6680 0x7300 0x8000 0x7 0x0 0x0 0x9 0x28 0x31 0x8000 0x6b80 0x7080 0x8 0x0 0xa 0x13 0x28 0x31 0x8000 0x7400 0x8000 0x9 0x0 0x14 0x1d 0x28 0x31 0x7a00 0x7700 0x8000 0xa 0x0 0x1e 0x27 0x28 0x31 0x7600 0x7780 0x8000 0xb 0x0 0x28 0x31 0x28 0x31 0x6f80 0x7980 0x8000 0xc 0x0 0x32 0x3b 0x28 0x31 0x7080 0x7e80 0x8000 0xd 0x0 0x0 0x9 0x14 0x27 0x8000 0x6b00 0x6d00 0xe 0x0 0xa 0x13 0x14 0x27 0x8000 0x7380 0x7480 0xff 0x0 0x14 0x27 0x14 0x27 0x8000 0x8000 0x8000 0x10 0x0 0x28 0x31 0x14 0x27 0x7500 0x8000 0x7e80 0x11 0x0 0x32 0x3b 0x14 0x27 0x7100 0x8000 0x7c80 0x12 0x0 0x0 0x9 0x0 0x9 0x8000 0x6900 0x6500 0x13 0x0 0x0 0x13 0xa 0x13 0x8000 0x7300 0x6f00 0x13 0x0 0xa 0x13 0x0 0x9 0x8000 0x7300 0x6f00 0x14 0x0 0x14 0x27 0xa 0x13 0x7f00 0x8000 0x7900 0x15 0x0 0x14 0x27 0x0 0x9 0x7e80 0x8000 0x7680 0x16 0x0 0x28 0x31 0xa 0x13 0x7380 0x8000 0x7600 0x17 0x0 0x32 0x3b 0xa 0x13 0x7080 0x8000 0x7900 0x18 0x0 0x28 0x31 0x0 0x9 0x7a00 0x8000 0x7580 0x19 0x0 0x32 0x3b 0x0 0x9 0x6f00 0x8000 0x7200>;
			};

			somc,renesas_auo_1080p_panel {
				qcom,mdss-dsi-panel-name = "auo renesas 1080p video";
				qcom,mdss-dsi-panel-controller = <0x23>;
				qcom,mdss-dsi-panel-type = "dsi_video_mode";
				qcom,mdss-dsi-panel-destination = "display_1";
				qcom,mdss-dsi-panel-framerate = <0x3c>;
				qcom,mdss-dsi-virtual-channel-id = <0x0>;
				qcom,mdss-dsi-stream = <0x0>;
				qcom,mdss-dsi-panel-width = <0x438>;
				qcom,mdss-dsi-panel-height = <0x780>;
				qcom,mdss-dsi-h-front-porch = <0x68>;
				qcom,mdss-dsi-h-back-porch = <0x38>;
				qcom,mdss-dsi-h-pulse-width = <0x14>;
				qcom,mdss-dsi-h-sync-skew = <0x0>;
				qcom,mdss-dsi-v-back-porch = <0x14>;
				qcom,mdss-dsi-v-front-porch = <0x18>;
				qcom,mdss-dsi-v-pulse-width = <0xa>;
				qcom,mdss-dsi-h-left-border = <0x0>;
				qcom,mdss-dsi-h-right-border = <0x0>;
				qcom,mdss-dsi-v-top-border = <0x0>;
				qcom,mdss-dsi-v-bottom-border = <0x0>;
				qcom,mdss-dsi-bpp = <0x18>;
				qcom,mdss-dsi-underflow-color = <0x0>;
				qcom,mdss-dsi-border-color = <0x0>;
				somc,mdss-dsi-init-command = [15 01 00 00 00 00 02 35 01 29 01 00 00 00 00 02 b0 04 29 01 00 00 00 00 08 c2 30 f7 84 1b 0c 00 00 29 01 00 00 00 00 02 d6 01 05 01 00 00 00 00 01 29];
				qcom,mdss-dsi-on-command = <0x5010000 0x78000111>;
				qcom,mdss-dsi-off-command = <0x5010000 0x128 0x5010000 0x43000110>;
				qcom,mdss-dsi-on-command-state = "dsi_lp_mode";
				qcom,mdss-dsi-off-command-state = "dsi_hs_mode";
				qcom,mdss-dsi-h-sync-pulse = <0x1>;
				qcom,mdss-dsi-traffic-mode = "non_burst_sync_event";
				qcom,mdss-dsi-bllp-eof-power-mode;
				qcom,mdss-dsi-bllp-power-mode;
				qcom,mdss-dsi-lane-0-state;
				qcom,mdss-dsi-lane-1-state;
				qcom,mdss-dsi-lane-2-state;
				qcom,mdss-dsi-lane-3-state;
				qcom,mdss-dsi-panel-timings = <0xe6382600 0x686c2a3c 0x2c030400>;
				qcom,mdss-dsi-t-clk-post = <0x2>;
				qcom,mdss-dsi-t-clk-pre = <0x2b>;
				qcom,mdss-dsi-bl-min-level = <0x1>;
				qcom,mdss-dsi-bl-max-level = <0xff>;
				qcom,mdss-brightness-max-level = <0xff>;
				qcom,mdss-dsi-dma-trigger = "trigger_sw";
				qcom,mdss-dsi-mdp-trigger = "none";
				qcom,mdss-dsi-bl-pmic-control-type = "bl_ctrl_wled";
				qcom,mdss-dsi-pan-enable-dynamic-fps;
				qcom,mdss-dsi-pan-fps-update = "dfps_suspend_resume_mode";
				qcom,cont-splash-enabled;
				qcom,mdss-dsi-tx-eot-append;
				somc,driver-ic = <0x0>;
				somc,mul-channel-scaling = <0x3>;
				somc,mdss-phy-size-mm = <0x40 0x72>;
				somc,mdss-dsi-lane-config = [00 c2 ef 00 00 00 00 01 75 00 c2 ef 00 00 00 00 01 75 00 c2 ef 00 00 00 00 01 75 00 c2 ef 00 00 00 00 01 75 00 02 45 00 00 00 00 01 97];
				somc,mdss-dsi-disp-on-in-hs = <0x1>;
				somc,lcd-id = <0x1>;
				somc,lcd-id-adc = <0x347d8 0x3e800>;
				somc,pw-on-rst-seq = <0x1 0xa 0x0 0x1 0x1 0xa>;
				somc,pw-off-rst-seq = <0x0 0x0>;
				somc,mdss-dsi-pre-uv-command = [23 01 00 00 00 00 02 b0 04];
				somc,mdss-dsi-uv-command = <0x6010000 0x1da 0x6010000 0x1dc>;
				somc,mdss-dsi-uv-param-type = <0x4>;
				somc,mdss-dsi-pcc-table-size = <0x49>;
				somc,mdss-dsi-pcc-table = <0x0 0x1 0x10 0x13 0x28 0x2b 0x8000 0x7400 0x8000 0x0 0x2 0x14 0x17 0x28 0x2b 0x7a80 0x7400 0x7e00 0x0 0x3 0x18 0x1b 0x28 0x2b 0x7480 0x7380 0x8000 0x0 0x4 0x1c 0x1f 0x28 0x2b 0x7280 0x7380 0x8000 0x0 0x5 0x20 0x23 0x28 0x2b 0x6e00 0x7400 0x8000 0x0 0x6 0xc 0xf 0x24 0x27 0x7f80 0x7200 0x7c00 0x0 0x7 0x10 0x13 0x24 0x27 0x8000 0x7400 0x7d80 0x0 0x8 0x14 0x17 0x24 0x27 0x7d00 0x7700 0x7e00 0x0 0x9 0x18 0x1b 0x24 0x27 0x7700 0x7600 0x8000 0x0 0xa 0x1c 0x1f 0x24 0x27 0x7380 0x7500 0x7c00 0x0 0xb 0x20 0x23 0x24 0x27 0x6f00 0x7500 0x7e80 0x0 0xc 0xc 0xf 0x20 0x23 0x7f80 0x7200 0x7900 0x0 0xd 0x10 0x13 0x20 0x23 0x8000 0x7400 0x7b00 0x0 0xe 0x14 0x17 0x20 0x23 0x7a80 0x7400 0x7b00 0x0 0xf 0x18 0x1b 0x20 0x23 0x7800 0x7700 0x7e80 0x0 0x10 0x1c 0x1f 0x20 0x23 0x7780 0x7900 0x7f80 0x0 0x11 0x20 0x23 0x20 0x23 0x7300 0x7900 0x7f00 0x0 0x12 0x24 0x27 0x20 0x23 0x7100 0x7980 0x8000 0x0 0x13 0xc 0xf 0x1c 0x1f 0x7f80 0x7200 0x7700 0x0 0x14 0x10 0x13 0x1c 0x1f 0x7c00 0x7000 0x7580 0x0 0x15 0x14 0x17 0x1c 0x1f 0x7f80 0x7900 0x7e00 0x0 0x16 0x18 0x1b 0x1c 0x1f 0x7c00 0x7a00 0x7d80 0x0 0x17 0x1c 0x1f 0x1c 0x1f 0x7900 0x7a00 0x7e00 0x0 0x18 0x20 0x23 0x1c 0x1f 0x7600 0x7c80 0x8000 0x0 0x19 0x24 0x27 0x1c 0x1f 0x7300 0x7c00 0x7e80 0x0 0x1a 0xc 0xf 0x18 0x1b 0x8000 0x7200 0x7300 0x0 0x1b 0x10 0x13 0x18 0x1b 0x7e80 0x7200 0x7500 0x0 0x1c 0x14 0x17 0x18 0x1b 0x7f00 0x7900 0x7b80 0x0 0x1d 0x18 0x1b 0x18 0x1b 0x7f00 0x7d00 0x7e00 0x0 0x1e 0x1c 0x1f 0x18 0x1b 0x7d00 0x7d80 0x8000 0x0 0x1f 0x20 0x23 0x18 0x1b 0x7900 0x7f00 0x8000 0x0 0x20 0x24 0x27 0x18 0x1b 0x7780 0x8000 0x8000 0x0 0x21 0x10 0x13 0x14 0x17 0x7f80 0x7380 0x7200 0x0 0x22 0x14 0x17 0x14 0x17 0x7f00 0x7900 0x7900 0x0 0x23 0x18 0x1b 0x14 0x17 0x7f00 0x7d00 0x7b80 0xff 0x0 0x1c 0x1f 0x14 0x17 0x8000 0x8000 0x8000 0x0 0x24 0x20 0x23 0x14 0x17 0x7a00 0x8000 0x7e80 0x0 0x25 0x24 0x27 0x14 0x17 0x7780 0x8000 0x7d80 0x0 0x26 0x10 0x13 0x10 0x13 0x8000 0x7400 0x7000 0x0 0x27 0x14 0x17 0x10 0x13 0x7f80 0x7900 0x7680 0x0 0x28 0x18 0x1b 0x10 0x13 0x8000 0x7d80 0x7980 0x0 0x29 0x1c 0x1f 0x10 0x13 0x8000 0x8000 0x7c00 0x0 0x2a 0x20 0x23 0x10 0x13 0x7a00 0x8000 0x7c00 0x0 0x2b 0x10 0x13 0xc 0xf 0x7f80 0x7480 0x6f00 0x0 0x2c 0x14 0x17 0xc 0xf 0x7f80 0x7900 0x7400 0x0 0x2d 0x18 0x1b 0xc 0xf 0x7f80 0x7d80 0x7680 0x0 0x2e 0x1c 0x1f 0xc 0xf 0x8000 0x8000 0x7980 0x1 0x0 0x0 0x9 0x32 0x3b 0x8000 0x6d00 0x8000 0x2 0x0 0xa 0x13 0x32 0x3b 0x7a00 0x7100 0x8000 0x3 0x0 0x14 0x1d 0x32 0x3b 0x7400 0x7180 0x8000 0x4 0x0 0x1e 0x27 0x32 0x3b 0x7100 0x7200 0x8000 0x5 0x0 0x28 0x31 0x32 0x3b 0x6c80 0x7180 0x8000 0x6 0x0 0x32 0x3b 0x32 0x3b 0x6680 0x7300 0x8000 0x7 0x0 0x0 0x9 0x28 0x31 0x8000 0x6b80 0x7080 0x8 0x0 0xa 0x13 0x28 0x31 0x8000 0x7400 0x8000 0x9 0x0 0x14 0x1d 0x28 0x31 0x7a00 0x7700 0x8000 0xa 0x0 0x1e 0x27 0x28 0x31 0x7600 0x7780 0x8000 0xb 0x0 0x28 0x31 0x28 0x31 0x6f80 0x7980 0x8000 0xc 0x0 0x32 0x3b 0x28 0x31 0x7080 0x7e80 0x8000 0xd 0x0 0x0 0x9 0x14 0x27 0x8000 0x6b00 0x6d00 0xe 0x0 0xa 0x13 0x14 0x27 0x8000 0x7380 0x7480 0xff 0x0 0x14 0x27 0x14 0x27 0x8000 0x8000 0x8000 0x10 0x0 0x28 0x31 0x14 0x27 0x7500 0x8000 0x7e80 0x11 0x0 0x32 0x3b 0x14 0x27 0x7100 0x8000 0x7c80 0x12 0x0 0x0 0x9 0x0 0x9 0x8000 0x6900 0x6500 0x13 0x0 0x0 0x13 0xa 0x13 0x8000 0x7300 0x6f00 0x13 0x0 0xa 0x13 0x0 0x9 0x8000 0x7300 0x6f00 0x14 0x0 0x14 0x27 0xa 0x13 0x7f00 0x8000 0x7900 0x15 0x0 0x14 0x27 0x0 0x9 0x7e80 0x8000 0x7680 0x16 0x0 0x28 0x31 0xa 0x13 0x7380 0x8000 0x7600 0x17 0x0 0x32 0x3b 0xa 0x13 0x7080 0x8000 0x7900 0x18 0x0 0x28 0x31 0x0 0x9 0x7a00 0x8000 0x7580 0x19 0x0 0x32 0x3b 0x0 0x9 0x6f00 0x8000 0x7200>;
			};

			somc,renesas_jdi_1080p_panel {
				qcom,mdss-dsi-panel-name = "jdi renesas 1080p video";
				qcom,mdss-dsi-panel-controller = <0x23>;
				qcom,mdss-dsi-panel-type = "dsi_video_mode";
				qcom,mdss-dsi-panel-destination = "display_1";
				qcom,mdss-dsi-panel-framerate = <0x3c>;
				qcom,mdss-dsi-virtual-channel-id = <0x0>;
				qcom,mdss-dsi-stream = <0x0>;
				qcom,mdss-dsi-panel-width = <0x438>;
				qcom,mdss-dsi-panel-height = <0x780>;
				qcom,mdss-dsi-h-front-porch = <0x70>;
				qcom,mdss-dsi-h-back-porch = <0x4c>;
				qcom,mdss-dsi-h-pulse-width = <0x4>;
				qcom,mdss-dsi-h-sync-skew = <0x0>;
				qcom,mdss-dsi-v-back-porch = <0x4>;
				qcom,mdss-dsi-v-front-porch = <0x1b>;
				qcom,mdss-dsi-v-pulse-width = <0x4>;
				qcom,mdss-dsi-h-left-border = <0x0>;
				qcom,mdss-dsi-h-right-border = <0x0>;
				qcom,mdss-dsi-v-top-border = <0x0>;
				qcom,mdss-dsi-v-bottom-border = <0x0>;
				qcom,mdss-dsi-bpp = <0x18>;
				qcom,mdss-dsi-underflow-color = <0x0>;
				qcom,mdss-dsi-border-color = <0x0>;
				somc,mdss-dsi-init-command = [05 01 00 00 05 00 01 01 23 01 00 00 00 00 02 b0 00 23 01 00 00 00 00 02 00 00 23 01 00 00 00 00 02 00 00 29 01 00 00 00 00 19 c7 08 12 1b 24 31 48 40 52 5e 61 6a 76 08 12 1b 24 31 48 40 52 5e 61 6a 76 29 01 00 00 00 00 19 c8 08 12 1b 24 31 49 41 53 5e 61 6a 76 08 12 1b 24 31 49 41 53 5e 61 6a 76 29 01 00 00 00 00 19 c9 08 12 1b 24 31 47 3f 52 5e 61 6a 76 08 12 1b 24 31 47 3f 52 5e 61 6a 76 29 01 00 00 00 00 1b d3 1b 33 bb cc c4 33 33 33 00 01 00 a0 d8 a0 06 2b 33 33 22 70 02 2b 43 3d bf 99 23 01 00 00 00 00 02 d6 01];
				qcom,mdss-dsi-on-command = <0x5010000 0x78000111 0x5010000 0x129>;
				qcom,mdss-dsi-off-command = <0x5010000 0x14000128 0x5010000 0x50000110>;
				qcom,mdss-dsi-on-command-state = "dsi_lp_mode";
				qcom,mdss-dsi-off-command-state = "dsi_hs_mode";
				qcom,mdss-dsi-h-sync-pulse = <0x1>;
				qcom,mdss-dsi-traffic-mode = "non_burst_sync_event";
				qcom,mdss-dsi-bllp-eof-power-mode;
				qcom,mdss-dsi-bllp-power-mode;
				qcom,mdss-dsi-lane-0-state;
				qcom,mdss-dsi-lane-1-state;
				qcom,mdss-dsi-lane-2-state;
				qcom,mdss-dsi-lane-3-state;
				qcom,mdss-dsi-panel-timings = <0xe6382600 0x686c2a3c 0x2c030400>;
				qcom,mdss-dsi-lp11-init;
				qcom,mdss-dsi-t-clk-post = <0x2>;
				qcom,mdss-dsi-t-clk-pre = <0x2b>;
				qcom,mdss-dsi-bl-min-level = <0x1>;
				qcom,mdss-dsi-bl-max-level = <0xff>;
				qcom,mdss-brightness-max-level = <0xff>;
				qcom,mdss-dsi-dma-trigger = "trigger_sw";
				qcom,mdss-dsi-mdp-trigger = "none";
				qcom,mdss-dsi-bl-pmic-control-type = "bl_ctrl_wled";
				qcom,mdss-dsi-pan-enable-dynamic-fps;
				qcom,mdss-dsi-pan-fps-update = "dfps_suspend_resume_mode";
				qcom,cont-splash-enabled;
				qcom,mdss-dsi-tx-eot-append;
				somc,driver-ic = <0x0>;
				somc,mul-channel-scaling = <0x3>;
				somc,mdss-phy-size-mm = <0x40 0x72>;
				somc,mdss-dsi-lane-config = [00 c2 ef 00 00 00 00 01 75 00 c2 ef 00 00 00 00 01 75 00 c2 ef 00 00 00 00 01 75 00 c2 ef 00 00 00 00 01 75 00 02 45 00 00 00 00 01 97];
				somc,mdss-dsi-disp-on-in-hs = <0x1>;
				somc,lcd-id = <0x1>;
				somc,lcd-id-adc = <0x562e8 0x65130>;
				somc,disp-en-on-pre = <0x5>;
				somc,disp-en-on-post = <0xf>;
				somc,disp-en-off-post = <0x46>;
				somc,pw-on-rst-seq = <0x1 0xa>;
				somc,pw-off-rst-seq = <0x0 0x0>;
				somc,mdss-dsi-pre-uv-command = [23 01 00 00 00 00 02 b0 04];
				somc,mdss-dsi-uv-command = <0x6010000 0x1da 0x6010000 0x1db>;
				somc,mdss-dsi-uv-param-type = <0x4>;
				somc,mdss-dsi-pcc-table-size = <0x49>;
				somc,mdss-dsi-pcc-table = <0x0 0x1 0x10 0x13 0x28 0x2b 0x8000 0x7400 0x8000 0x0 0x2 0x14 0x17 0x28 0x2b 0x7a80 0x7400 0x7e00 0x0 0x3 0x18 0x1b 0x28 0x2b 0x7480 0x7380 0x8000 0x0 0x4 0x1c 0x1f 0x28 0x2b 0x7280 0x7380 0x8000 0x0 0x5 0x20 0x23 0x28 0x2b 0x6e00 0x7400 0x8000 0x0 0x6 0xc 0xf 0x24 0x27 0x7f80 0x7200 0x7c00 0x0 0x7 0x10 0x13 0x24 0x27 0x8000 0x7400 0x7d80 0x0 0x8 0x14 0x17 0x24 0x27 0x7d00 0x7700 0x7e00 0x0 0x9 0x18 0x1b 0x24 0x27 0x7700 0x7600 0x8000 0x0 0xa 0x1c 0x1f 0x24 0x27 0x7380 0x7500 0x7c00 0x0 0xb 0x20 0x23 0x24 0x27 0x6f00 0x7500 0x7e80 0x0 0xc 0xc 0xf 0x20 0x23 0x7f80 0x7200 0x7900 0x0 0xd 0x10 0x13 0x20 0x23 0x8000 0x7400 0x7b00 0x0 0xe 0x14 0x17 0x20 0x23 0x7a80 0x7400 0x7b00 0x0 0xf 0x18 0x1b 0x20 0x23 0x7800 0x7700 0x7e80 0x0 0x10 0x1c 0x1f 0x20 0x23 0x7780 0x7900 0x7f80 0x0 0x11 0x20 0x23 0x20 0x23 0x7300 0x7900 0x7f00 0x0 0x12 0x24 0x27 0x20 0x23 0x7100 0x7980 0x8000 0x0 0x13 0xc 0xf 0x1c 0x1f 0x7f80 0x7200 0x7700 0x0 0x14 0x10 0x13 0x1c 0x1f 0x7c00 0x7000 0x7580 0x0 0x15 0x14 0x17 0x1c 0x1f 0x7f80 0x7900 0x7e00 0x0 0x16 0x18 0x1b 0x1c 0x1f 0x7c00 0x7a00 0x7d80 0x0 0x17 0x1c 0x1f 0x1c 0x1f 0x7900 0x7a00 0x7e00 0x0 0x18 0x20 0x23 0x1c 0x1f 0x7600 0x7c80 0x8000 0x0 0x19 0x24 0x27 0x1c 0x1f 0x7300 0x7c00 0x7e80 0x0 0x1a 0xc 0xf 0x18 0x1b 0x8000 0x7200 0x7300 0x0 0x1b 0x10 0x13 0x18 0x1b 0x7e80 0x7200 0x7500 0x0 0x1c 0x14 0x17 0x18 0x1b 0x7f00 0x7900 0x7b80 0x0 0x1d 0x18 0x1b 0x18 0x1b 0x7f00 0x7d00 0x7e00 0x0 0x1e 0x1c 0x1f 0x18 0x1b 0x7d00 0x7d80 0x8000 0x0 0x1f 0x20 0x23 0x18 0x1b 0x7900 0x7f00 0x8000 0x0 0x20 0x24 0x27 0x18 0x1b 0x7780 0x8000 0x8000 0x0 0x21 0x10 0x13 0x14 0x17 0x7f80 0x7380 0x7200 0x0 0x22 0x14 0x17 0x14 0x17 0x7f00 0x7900 0x7900 0x0 0x23 0x18 0x1b 0x14 0x17 0x7f00 0x7d00 0x7b80 0xff 0x0 0x1c 0x1f 0x14 0x17 0x8000 0x8000 0x8000 0x0 0x24 0x20 0x23 0x14 0x17 0x7a00 0x8000 0x7e80 0x0 0x25 0x24 0x27 0x14 0x17 0x7780 0x8000 0x7d80 0x0 0x26 0x10 0x13 0x10 0x13 0x8000 0x7400 0x7000 0x0 0x27 0x14 0x17 0x10 0x13 0x7f80 0x7900 0x7680 0x0 0x28 0x18 0x1b 0x10 0x13 0x8000 0x7d80 0x7980 0x0 0x29 0x1c 0x1f 0x10 0x13 0x8000 0x8000 0x7c00 0x0 0x2a 0x20 0x23 0x10 0x13 0x7a00 0x8000 0x7c00 0x0 0x2b 0x10 0x13 0xc 0xf 0x7f80 0x7480 0x6f00 0x0 0x2c 0x14 0x17 0xc 0xf 0x7f80 0x7900 0x7400 0x0 0x2d 0x18 0x1b 0xc 0xf 0x7f80 0x7d80 0x7680 0x0 0x2e 0x1c 0x1f 0xc 0xf 0x8000 0x8000 0x7980 0x1 0x0 0x0 0x9 0x32 0x3b 0x8000 0x6d00 0x8000 0x2 0x0 0xa 0x13 0x32 0x3b 0x7a00 0x7100 0x8000 0x3 0x0 0x14 0x1d 0x32 0x3b 0x7400 0x7180 0x8000 0x4 0x0 0x1e 0x27 0x32 0x3b 0x7100 0x7200 0x8000 0x5 0x0 0x28 0x31 0x32 0x3b 0x6c80 0x7180 0x8000 0x6 0x0 0x32 0x3b 0x32 0x3b 0x6680 0x7300 0x8000 0x7 0x0 0x0 0x9 0x28 0x31 0x8000 0x6b80 0x7080 0x8 0x0 0xa 0x13 0x28 0x31 0x8000 0x7400 0x8000 0x9 0x0 0x14 0x1d 0x28 0x31 0x7a00 0x7700 0x8000 0xa 0x0 0x1e 0x27 0x28 0x31 0x7600 0x7780 0x8000 0xb 0x0 0x28 0x31 0x28 0x31 0x6f80 0x7980 0x8000 0xc 0x0 0x32 0x3b 0x28 0x31 0x7080 0x7e80 0x8000 0xd 0x0 0x0 0x9 0x14 0x27 0x8000 0x6b00 0x6d00 0xe 0x0 0xa 0x13 0x14 0x27 0x8000 0x7380 0x7480 0xff 0x0 0x14 0x27 0x14 0x27 0x8000 0x8000 0x8000 0x10 0x0 0x28 0x31 0x14 0x27 0x7500 0x8000 0x7e80 0x11 0x0 0x32 0x3b 0x14 0x27 0x7100 0x8000 0x7c80 0x12 0x0 0x0 0x9 0x0 0x9 0x8000 0x6900 0x6500 0x13 0x0 0x0 0x13 0xa 0x13 0x8000 0x7300 0x6f00 0x13 0x0 0xa 0x13 0x0 0x9 0x8000 0x7300 0x6f00 0x14 0x0 0x14 0x27 0xa 0x13 0x7f00 0x8000 0x7900 0x15 0x0 0x14 0x27 0x0 0x9 0x7e80 0x8000 0x7680 0x16 0x0 0x28 0x31 0xa 0x13 0x7380 0x8000 0x7600 0x17 0x0 0x32 0x3b 0xa 0x13 0x7080 0x8000 0x7900 0x18 0x0 0x28 0x31 0x0 0x9 0x7a00 0x8000 0x7580 0x19 0x0 0x32 0x3b 0x0 0x9 0x6f00 0x8000 0x7200>;
			};

			somc,novatek_jdi_1080p_panel {
				qcom,mdss-dsi-panel-name = "jdi novatek 1080p video";
				qcom,mdss-dsi-panel-controller = <0x23>;
				qcom,mdss-dsi-panel-type = "dsi_video_mode";
				qcom,mdss-dsi-panel-destination = "display_1";
				qcom,mdss-dsi-panel-framerate = <0x3c>;
				qcom,mdss-dsi-virtual-channel-id = <0x0>;
				qcom,mdss-dsi-stream = <0x0>;
				qcom,mdss-dsi-panel-width = <0x438>;
				qcom,mdss-dsi-panel-height = <0x780>;
				qcom,mdss-dsi-h-front-porch = <0x70>;
				qcom,mdss-dsi-h-back-porch = <0x4c>;
				qcom,mdss-dsi-h-pulse-width = <0x4>;
				qcom,mdss-dsi-h-sync-skew = <0x0>;
				qcom,mdss-dsi-v-back-porch = <0x4>;
				qcom,mdss-dsi-v-front-porch = <0x1b>;
				qcom,mdss-dsi-v-pulse-width = <0x4>;
				qcom,mdss-dsi-h-left-border = <0x0>;
				qcom,mdss-dsi-h-right-border = <0x0>;
				qcom,mdss-dsi-v-top-border = <0x0>;
				qcom,mdss-dsi-v-bottom-border = <0x0>;
				qcom,mdss-dsi-bpp = <0x18>;
				qcom,mdss-dsi-underflow-color = <0x0>;
				qcom,mdss-dsi-border-color = <0x0>;
				somc,mdss-dsi-init-command = [05 01 00 00 0a 00 01 01 23 01 00 00 00 00 02 ff 01 23 01 00 00 00 00 02 75 00 23 01 00 00 00 00 02 76 30 23 01 00 00 00 00 02 77 00 23 01 00 00 00 00 02 78 43 23 01 00 00 00 00 02 79 00 23 01 00 00 00 00 02 7a 61 23 01 00 00 00 00 02 7b 00 23 01 00 00 00 00 02 7c 7d 23 01 00 00 00 00 02 7d 00 23 01 00 00 00 00 02 7e 98 23 01 00 00 00 00 02 7f 00 23 01 00 00 00 00 02 80 ae 23 01 00 00 00 00 02 81 00 23 01 00 00 00 00 02 82 c0 23 01 00 00 00 00 02 83 00 23 01 00 00 00 00 02 84 cd 23 01 00 00 00 00 02 85 00 23 01 00 00 00 00 02 86 db 23 01 00 00 00 00 02 87 01 23 01 00 00 00 00 02 88 0a 23 01 00 00 00 00 02 89 01 23 01 00 00 00 00 02 8a 2a 23 01 00 00 00 00 02 8b 01 23 01 00 00 00 00 02 8c 66 23 01 00 00 00 00 02 8d 01 23 01 00 00 00 00 02 8e 95 23 01 00 00 00 00 02 8f 01 23 01 00 00 00 00 02 90 d8 23 01 00 00 00 00 02 91 02 23 01 00 00 00 00 02 92 1a 23 01 00 00 00 00 02 93 02 23 01 00 00 00 00 02 94 1c 23 01 00 00 00 00 02 95 02 23 01 00 00 00 00 02 96 5e 23 01 00 00 00 00 02 97 02 23 01 00 00 00 00 02 98 9a 23 01 00 00 00 00 02 99 02 23 01 00 00 00 00 02 9a bf 23 01 00 00 00 00 02 9b 02 23 01 00 00 00 00 02 9c ed 23 01 00 00 00 00 02 9d 03 23 01 00 00 00 00 02 9e 0b 23 01 00 00 00 00 02 9f 03 23 01 00 00 00 00 02 a0 36 23 01 00 00 00 00 02 a2 03 23 01 00 00 00 00 02 a3 3b 23 01 00 00 00 00 02 a4 03 23 01 00 00 00 00 02 a5 40 23 01 00 00 00 00 02 a6 03 23 01 00 00 00 00 02 a7 45 23 01 00 00 00 00 02 a9 03 23 01 00 00 00 00 02 aa 54 23 01 00 00 00 00 02 ab 03 23 01 00 00 00 00 02 ac 70 23 01 00 00 00 00 02 ad 03 23 01 00 00 00 00 02 ae 8e 23 01 00 00 00 00 02 af 03 23 01 00 00 00 00 02 b0 b2 23 01 00 00 00 00 02 b1 03 23 01 00 00 00 00 02 b2 c9 23 01 00 00 00 00 02 b3 00 23 01 00 00 00 00 02 b4 30 23 01 00 00 00 00 02 b5 00 23 01 00 00 00 00 02 b6 43 23 01 00 00 00 00 02 b7 00 23 01 00 00 00 00 02 b8 61 23 01 00 00 00 00 02 b9 00 23 01 00 00 00 00 02 ba 7d 23 01 00 00 00 00 02 bb 00 23 01 00 00 00 00 02 bc 98 23 01 00 00 00 00 02 bd 00 23 01 00 00 00 00 02 be ae 23 01 00 00 00 00 02 bf 00 23 01 00 00 00 00 02 c0 c0 23 01 00 00 00 00 02 c1 00 23 01 00 00 00 00 02 c2 cd 23 01 00 00 00 00 02 c3 00 23 01 00 00 00 00 02 c4 db 23 01 00 00 00 00 02 c5 01 23 01 00 00 00 00 02 c6 0a 23 01 00 00 00 00 02 c7 01 23 01 00 00 00 00 02 c8 2a 23 01 00 00 00 00 02 c9 01 23 01 00 00 00 00 02 ca 66 23 01 00 00 00 00 02 cb 01 23 01 00 00 00 00 02 cc 95 23 01 00 00 00 00 02 cd 01 23 01 00 00 00 00 02 ce d8 23 01 00 00 00 00 02 cf 02 23 01 00 00 00 00 02 d0 1a 23 01 00 00 00 00 02 d1 02 23 01 00 00 00 00 02 d2 1c 23 01 00 00 00 00 02 d3 02 23 01 00 00 00 00 02 d4 5e 23 01 00 00 00 00 02 d5 02 23 01 00 00 00 00 02 d6 9a 23 01 00 00 00 00 02 d7 02 23 01 00 00 00 00 02 d8 bf 23 01 00 00 00 00 02 d9 02 23 01 00 00 00 00 02 da ed 23 01 00 00 00 00 02 db 03 23 01 00 00 00 00 02 dc 0b 23 01 00 00 00 00 02 dd 03 23 01 00 00 00 00 02 de 36 23 01 00 00 00 00 02 df 03 23 01 00 00 00 00 02 e0 3b 23 01 00 00 00 00 02 e1 03 23 01 00 00 00 00 02 e2 40 23 01 00 00 00 00 02 e3 03 23 01 00 00 00 00 02 e4 45 23 01 00 00 00 00 02 e5 03 23 01 00 00 00 00 02 e6 54 23 01 00 00 00 00 02 e7 03 23 01 00 00 00 00 02 e8 70 23 01 00 00 00 00 02 e9 03 23 01 00 00 00 00 02 ea 8e 23 01 00 00 00 00 02 eb 03 23 01 00 00 00 00 02 ec b2 23 01 00 00 00 00 02 ed 03 23 01 00 00 00 00 02 ee c9 23 01 00 00 00 00 02 ef 00 23 01 00 00 00 00 02 f0 30 23 01 00 00 00 00 02 f1 00 23 01 00 00 00 00 02 f2 43 23 01 00 00 00 00 02 f3 00 23 01 00 00 00 00 02 f4 61 23 01 00 00 00 00 02 f5 00 23 01 00 00 00 00 02 f6 7d 23 01 00 00 00 00 02 f7 00 23 01 00 00 00 00 02 f8 98 23 01 00 00 00 00 02 f9 00 23 01 00 00 00 00 02 fa ae 23 01 00 00 00 00 02 fb 01 23 01 00 00 00 00 02 ff 02 23 01 00 00 00 00 02 00 00 23 01 00 00 00 00 02 01 c0 23 01 00 00 00 00 02 02 00 23 01 00 00 00 00 02 03 cd 23 01 00 00 00 00 02 04 00 23 01 00 00 00 00 02 05 db 23 01 00 00 00 00 02 06 01 23 01 00 00 00 00 02 07 0a 23 01 00 00 00 00 02 08 01 23 01 00 00 00 00 02 09 2a 23 01 00 00 00 00 02 0a 01 23 01 00 00 00 00 02 0b 69 23 01 00 00 00 00 02 0c 01 23 01 00 00 00 00 02 0d 99 23 01 00 00 00 00 02 0e 01 23 01 00 00 00 00 02 0f de 23 01 00 00 00 00 02 10 02 23 01 00 00 00 00 02 11 20 23 01 00 00 00 00 02 12 02 23 01 00 00 00 00 02 13 22 23 01 00 00 00 00 02 14 02 23 01 00 00 00 00 02 15 64 23 01 00 00 00 00 02 16 02 23 01 00 00 00 00 02 17 a0 23 01 00 00 00 00 02 18 02 23 01 00 00 00 00 02 19 c4 23 01 00 00 00 00 02 1a 02 23 01 00 00 00 00 02 1b f3 23 01 00 00 00 00 02 1c 03 23 01 00 00 00 00 02 1d 0f 23 01 00 00 00 00 02 1e 03 23 01 00 00 00 00 02 1f 36 23 01 00 00 00 00 02 20 03 23 01 00 00 00 00 02 21 3b 23 01 00 00 00 00 02 22 03 23 01 00 00 00 00 02 23 40 23 01 00 00 00 00 02 24 03 23 01 00 00 00 00 02 25 45 23 01 00 00 00 00 02 26 03 23 01 00 00 00 00 02 27 54 23 01 00 00 00 00 02 28 03 23 01 00 00 00 00 02 29 70 23 01 00 00 00 00 02 2a 03 23 01 00 00 00 00 02 2b 8e 23 01 00 00 00 00 02 2d 03 23 01 00 00 00 00 02 2f b2 23 01 00 00 00 00 02 30 03 23 01 00 00 00 00 02 31 c9 23 01 00 00 00 00 02 32 00 23 01 00 00 00 00 02 33 30 23 01 00 00 00 00 02 34 00 23 01 00 00 00 00 02 35 43 23 01 00 00 00 00 02 36 00 23 01 00 00 00 00 02 37 61 23 01 00 00 00 00 02 38 00 23 01 00 00 00 00 02 39 7d 23 01 00 00 00 00 02 3a 00 23 01 00 00 00 00 02 3b 98 23 01 00 00 00 00 02 3d 00 23 01 00 00 00 00 02 3f ae 23 01 00 00 00 00 02 40 00 23 01 00 00 00 00 02 41 c0 23 01 00 00 00 00 02 42 00 23 01 00 00 00 00 02 43 cd 23 01 00 00 00 00 02 44 00 23 01 00 00 00 00 02 45 db 23 01 00 00 00 00 02 46 01 23 01 00 00 00 00 02 47 0a 23 01 00 00 00 00 02 48 01 23 01 00 00 00 00 02 49 2a 23 01 00 00 00 00 02 4a 01 23 01 00 00 00 00 02 4b 69 23 01 00 00 00 00 02 4c 01 23 01 00 00 00 00 02 4d 99 23 01 00 00 00 00 02 4e 01 23 01 00 00 00 00 02 4f de 23 01 00 00 00 00 02 50 02 23 01 00 00 00 00 02 51 20 23 01 00 00 00 00 02 52 02 23 01 00 00 00 00 02 53 22 23 01 00 00 00 00 02 54 02 23 01 00 00 00 00 02 55 64 23 01 00 00 00 00 02 56 02 23 01 00 00 00 00 02 58 a0 23 01 00 00 00 00 02 59 02 23 01 00 00 00 00 02 5a c4 23 01 00 00 00 00 02 5b 02 23 01 00 00 00 00 02 5c f3 23 01 00 00 00 00 02 5d 03 23 01 00 00 00 00 02 5e 0f 23 01 00 00 00 00 02 5f 03 23 01 00 00 00 00 02 60 36 23 01 00 00 00 00 02 61 03 23 01 00 00 00 00 02 62 3b 23 01 00 00 00 00 02 63 03 23 01 00 00 00 00 02 64 40 23 01 00 00 00 00 02 65 03 23 01 00 00 00 00 02 66 45 23 01 00 00 00 00 02 67 03 23 01 00 00 00 00 02 68 54 23 01 00 00 00 00 02 69 03 23 01 00 00 00 00 02 6a 70 23 01 00 00 00 00 02 6b 03 23 01 00 00 00 00 02 6c 8e 23 01 00 00 00 00 02 6d 03 23 01 00 00 00 00 02 6e b2 23 01 00 00 00 00 02 6f 03 23 01 00 00 00 00 02 70 c9 23 01 00 00 00 00 02 71 00 23 01 00 00 00 00 02 72 30 23 01 00 00 00 00 02 73 00 23 01 00 00 00 00 02 74 43 23 01 00 00 00 00 02 75 00 23 01 00 00 00 00 02 76 61 23 01 00 00 00 00 02 77 00 23 01 00 00 00 00 02 78 7d 23 01 00 00 00 00 02 79 00 23 01 00 00 00 00 02 7a 98 23 01 00 00 00 00 02 7b 00 23 01 00 00 00 00 02 7c ae 23 01 00 00 00 00 02 7d 00 23 01 00 00 00 00 02 7e c0 23 01 00 00 00 00 02 7f 00 23 01 00 00 00 00 02 80 cd 23 01 00 00 00 00 02 81 00 23 01 00 00 00 00 02 82 db 23 01 00 00 00 00 02 83 01 23 01 00 00 00 00 02 84 0a 23 01 00 00 00 00 02 85 01 23 01 00 00 00 00 02 86 2a 23 01 00 00 00 00 02 87 01 23 01 00 00 00 00 02 88 63 23 01 00 00 00 00 02 89 01 23 01 00 00 00 00 02 8a 90 23 01 00 00 00 00 02 8b 01 23 01 00 00 00 00 02 8c d2 23 01 00 00 00 00 02 8d 02 23 01 00 00 00 00 02 8e 14 23 01 00 00 00 00 02 8f 02 23 01 00 00 00 00 02 90 16 23 01 00 00 00 00 02 91 02 23 01 00 00 00 00 02 92 58 23 01 00 00 00 00 02 93 02 23 01 00 00 00 00 02 94 95 23 01 00 00 00 00 02 95 02 23 01 00 00 00 00 02 96 bc 23 01 00 00 00 00 02 97 02 23 01 00 00 00 00 02 98 ed 23 01 00 00 00 00 02 99 03 23 01 00 00 00 00 02 9a 0b 23 01 00 00 00 00 02 9b 03 23 01 00 00 00 00 02 9c 36 23 01 00 00 00 00 02 9d 03 23 01 00 00 00 00 02 9e 3b 23 01 00 00 00 00 02 9f 03 23 01 00 00 00 00 02 a0 40 23 01 00 00 00 00 02 a2 03 23 01 00 00 00 00 02 a3 45 23 01 00 00 00 00 02 a4 03 23 01 00 00 00 00 02 a5 54 23 01 00 00 00 00 02 a6 03 23 01 00 00 00 00 02 a7 70 23 01 00 00 00 00 02 a9 03 23 01 00 00 00 00 02 aa 8e 23 01 00 00 00 00 02 ab 03 23 01 00 00 00 00 02 ac b2 23 01 00 00 00 00 02 ad 03 23 01 00 00 00 00 02 ae c9 23 01 00 00 00 00 02 af 00 23 01 00 00 00 00 02 b0 30 23 01 00 00 00 00 02 b1 00 23 01 00 00 00 00 02 b2 43 23 01 00 00 00 00 02 b3 00 23 01 00 00 00 00 02 b4 61 23 01 00 00 00 00 02 b5 00 23 01 00 00 00 00 02 b6 7d 23 01 00 00 00 00 02 b7 00 23 01 00 00 00 00 02 b8 98 23 01 00 00 00 00 02 b9 00 23 01 00 00 00 00 02 ba ae 23 01 00 00 00 00 02 bb 00 23 01 00 00 00 00 02 bc c0 23 01 00 00 00 00 02 bd 00 23 01 00 00 00 00 02 be cd 23 01 00 00 00 00 02 bf 00 23 01 00 00 00 00 02 c0 db 23 01 00 00 00 00 02 c1 01 23 01 00 00 00 00 02 c2 0a 23 01 00 00 00 00 02 c3 01 23 01 00 00 00 00 02 c4 2a 23 01 00 00 00 00 02 c5 01 23 01 00 00 00 00 02 c6 63 23 01 00 00 00 00 02 c7 01 23 01 00 00 00 00 02 c8 90 23 01 00 00 00 00 02 c9 01 23 01 00 00 00 00 02 ca d2 23 01 00 00 00 00 02 cb 02 23 01 00 00 00 00 02 cc 14 23 01 00 00 00 00 02 cd 02 23 01 00 00 00 00 02 ce 16 23 01 00 00 00 00 02 cf 02 23 01 00 00 00 00 02 d0 58 23 01 00 00 00 00 02 d1 02 23 01 00 00 00 00 02 d2 95 23 01 00 00 00 00 02 d3 02 23 01 00 00 00 00 02 d4 bc 23 01 00 00 00 00 02 d5 02 23 01 00 00 00 00 02 d6 ed 23 01 00 00 00 00 02 d7 03 23 01 00 00 00 00 02 d8 0b 23 01 00 00 00 00 02 d9 03 23 01 00 00 00 00 02 da 36 23 01 00 00 00 00 02 db 03 23 01 00 00 00 00 02 dc 3b 23 01 00 00 00 00 02 dd 03 23 01 00 00 00 00 02 de 40 23 01 00 00 00 00 02 df 03 23 01 00 00 00 00 02 e0 45 23 01 00 00 00 00 02 e1 03 23 01 00 00 00 00 02 e2 54 23 01 00 00 00 00 02 e3 03 23 01 00 00 00 00 02 e4 70 23 01 00 00 00 00 02 e5 03 23 01 00 00 00 00 02 e6 8e 23 01 00 00 00 00 02 e7 03 23 01 00 00 00 00 02 e8 b2 23 01 00 00 00 00 02 e9 03 23 01 00 00 00 00 02 ea c9 23 01 00 00 00 00 02 fb 01 23 01 00 00 00 00 02 ff 01 23 01 00 00 00 00 02 0b 4b 23 01 00 00 00 00 02 0c 4b 23 01 00 00 00 00 02 0e a1 23 01 00 00 00 00 02 15 0b 23 01 00 00 00 00 02 16 0b 23 01 00 00 00 00 02 1b 1b 23 01 00 00 00 00 02 1c f5 23 01 00 00 00 00 02 01 44 23 01 00 00 00 00 02 5c 82 23 01 00 00 00 00 02 5e 02 23 01 00 00 00 00 02 60 0f 23 01 00 00 00 00 02 66 01 23 01 00 00 00 00 02 69 99 23 01 00 00 00 00 02 6d 33 23 01 00 00 00 00 02 fb 01 23 01 00 00 00 00 02 ff 05 23 01 00 00 00 00 02 35 6b 23 01 00 00 00 00 02 7e 02 23 01 00 00 00 00 02 7f 18 23 01 00 00 00 00 02 81 05 23 01 00 00 00 00 02 82 05 23 01 00 00 00 00 02 a6 04 23 01 00 00 00 00 02 84 03 23 01 00 00 00 00 02 85 04 15 01 00 00 00 00 02 c6 00 23 01 00 00 00 00 02 fb 01 23 01 00 00 00 00 02 ff ff 23 01 00 00 00 00 02 4f 03 23 01 00 00 00 00 02 fb 01 23 01 00 00 00 00 02 ff 00 15 01 00 00 00 00 02 d3 08 15 01 00 00 00 00 02 d4 1b 15 01 00 00 00 00 02 d5 50 15 01 00 00 00 00 02 d6 70];
				qcom,mdss-dsi-on-command = <0x5010000 0x78000111 0x5010000 0x129>;
				qcom,mdss-dsi-off-command = <0x5010000 0x14000128 0x5010000 0x50000110>;
				qcom,mdss-dsi-on-command-state = "dsi_lp_mode";
				qcom,mdss-dsi-off-command-state = "dsi_hs_mode";
				qcom,mdss-dsi-h-sync-pulse = <0x1>;
				qcom,mdss-dsi-traffic-mode = "non_burst_sync_event";
				qcom,mdss-dsi-bllp-eof-power-mode;
				qcom,mdss-dsi-bllp-power-mode;
				qcom,mdss-dsi-lane-0-state;
				qcom,mdss-dsi-lane-1-state;
				qcom,mdss-dsi-lane-2-state;
				qcom,mdss-dsi-lane-3-state;
				qcom,mdss-dsi-panel-timings = <0xe6382600 0x686c2a3c 0x2c030400>;
				qcom,mdss-dsi-lp11-init;
				qcom,mdss-dsi-t-clk-post = <0x2>;
				qcom,mdss-dsi-t-clk-pre = <0x2b>;
				qcom,mdss-dsi-bl-min-level = <0x1>;
				qcom,mdss-dsi-bl-max-level = <0xff>;
				qcom,mdss-brightness-max-level = <0xff>;
				qcom,mdss-dsi-dma-trigger = "trigger_sw";
				qcom,mdss-dsi-mdp-trigger = "none";
				qcom,mdss-dsi-bl-pmic-control-type = "bl_ctrl_wled";
				qcom,mdss-dsi-pan-enable-dynamic-fps;
				qcom,mdss-dsi-pan-fps-update = "dfps_suspend_resume_mode";
				qcom,cont-splash-enabled;
				qcom,mdss-dsi-tx-eot-append;
				somc,driver-ic = <0x1>;
				somc,mul-channel-scaling = <0x3>;
				somc,mdss-phy-size-mm = <0x40 0x72>;
				somc,mdss-dsi-lane-config = [00 c2 ef 00 00 00 00 01 75 00 c2 ef 00 00 00 00 01 75 00 c2 ef 00 00 00 00 01 75 00 c2 ef 00 00 00 00 01 75 00 02 45 00 00 00 00 01 97];
				somc,mdss-dsi-disp-on-in-hs = <0x1>;
				somc,lcd-id = <0x1>;
				somc,lcd-id-adc = <0x109618 0x12c898>;
				somc,disp-en-on-pre = <0x5>;
				somc,disp-en-on-post = <0x14>;
				somc,disp-en-off-post = <0x46>;
				somc,pw-on-rst-seq = <0x1 0xa>;
				somc,pw-off-rst-seq = <0x0 0x0>;
				somc,pw-down-period = <0xc8>;
				somc,mdss-dsi-pre-uv-command = [15 01 00 00 00 00 02 ff 00];
				somc,mdss-dsi-uv-command = <0x6010000 0x1da 0x6010000 0x1db>;
				somc,mdss-dsi-uv-param-type = <0x2>;
				somc,mdss-dsi-pcc-table-size = <0x49>;
				somc,mdss-dsi-pcc-table = <0x0 0x1 0x10 0x13 0x28 0x2b 0x8000 0x7400 0x8000 0x0 0x2 0x14 0x17 0x28 0x2b 0x7a80 0x7400 0x7e00 0x0 0x3 0x18 0x1b 0x28 0x2b 0x7480 0x7380 0x8000 0x0 0x4 0x1c 0x1f 0x28 0x2b 0x7280 0x7380 0x8000 0x0 0x5 0x20 0x23 0x28 0x2b 0x6e00 0x7400 0x8000 0x0 0x6 0xc 0xf 0x24 0x27 0x7f80 0x7200 0x7c00 0x0 0x7 0x10 0x13 0x24 0x27 0x8000 0x7400 0x7d80 0x0 0x8 0x14 0x17 0x24 0x27 0x7d00 0x7700 0x7e00 0x0 0x9 0x18 0x1b 0x24 0x27 0x7700 0x7600 0x8000 0x0 0xa 0x1c 0x1f 0x24 0x27 0x7380 0x7500 0x7c00 0x0 0xb 0x20 0x23 0x24 0x27 0x6f00 0x7500 0x7e80 0x0 0xc 0xc 0xf 0x20 0x23 0x7f80 0x7200 0x7900 0x0 0xd 0x10 0x13 0x20 0x23 0x8000 0x7400 0x7b00 0x0 0xe 0x14 0x17 0x20 0x23 0x7a80 0x7400 0x7b00 0x0 0xf 0x18 0x1b 0x20 0x23 0x7800 0x7700 0x7e80 0x0 0x10 0x1c 0x1f 0x20 0x23 0x7780 0x7900 0x7f80 0x0 0x11 0x20 0x23 0x20 0x23 0x7300 0x7900 0x7f00 0x0 0x12 0x24 0x27 0x20 0x23 0x7100 0x7980 0x8000 0x0 0x13 0xc 0xf 0x1c 0x1f 0x7f80 0x7200 0x7700 0x0 0x14 0x10 0x13 0x1c 0x1f 0x7c00 0x7000 0x7580 0x0 0x15 0x14 0x17 0x1c 0x1f 0x7f80 0x7900 0x7e00 0x0 0x16 0x18 0x1b 0x1c 0x1f 0x7c00 0x7a00 0x7d80 0x0 0x17 0x1c 0x1f 0x1c 0x1f 0x7900 0x7a00 0x7e00 0x0 0x18 0x20 0x23 0x1c 0x1f 0x7600 0x7c80 0x8000 0x0 0x19 0x24 0x27 0x1c 0x1f 0x7300 0x7c00 0x7e80 0x0 0x1a 0xc 0xf 0x18 0x1b 0x8000 0x7200 0x7300 0x0 0x1b 0x10 0x13 0x18 0x1b 0x7e80 0x7200 0x7500 0x0 0x1c 0x14 0x17 0x18 0x1b 0x7f00 0x7900 0x7b80 0x0 0x1d 0x18 0x1b 0x18 0x1b 0x7f00 0x7d00 0x7e00 0x0 0x1e 0x1c 0x1f 0x18 0x1b 0x7d00 0x7d80 0x8000 0x0 0x1f 0x20 0x23 0x18 0x1b 0x7900 0x7f00 0x8000 0x0 0x20 0x24 0x27 0x18 0x1b 0x7780 0x8000 0x8000 0x0 0x21 0x10 0x13 0x14 0x17 0x7f80 0x7380 0x7200 0x0 0x22 0x14 0x17 0x14 0x17 0x7f00 0x7900 0x7900 0x0 0x23 0x18 0x1b 0x14 0x17 0x7f00 0x7d00 0x7b80 0xff 0x0 0x1c 0x1f 0x14 0x17 0x8000 0x8000 0x8000 0x0 0x24 0x20 0x23 0x14 0x17 0x7a00 0x8000 0x7e80 0x0 0x25 0x24 0x27 0x14 0x17 0x7780 0x8000 0x7d80 0x0 0x26 0x10 0x13 0x10 0x13 0x8000 0x7400 0x7000 0x0 0x27 0x14 0x17 0x10 0x13 0x7f80 0x7900 0x7680 0x0 0x28 0x18 0x1b 0x10 0x13 0x8000 0x7d80 0x7980 0x0 0x29 0x1c 0x1f 0x10 0x13 0x8000 0x8000 0x7c00 0x0 0x2a 0x20 0x23 0x10 0x13 0x7a00 0x8000 0x7c00 0x0 0x2b 0x10 0x13 0xc 0xf 0x7f80 0x7480 0x6f00 0x0 0x2c 0x14 0x17 0xc 0xf 0x7f80 0x7900 0x7400 0x0 0x2d 0x18 0x1b 0xc 0xf 0x7f80 0x7d80 0x7680 0x0 0x2e 0x1c 0x1f 0xc 0xf 0x8000 0x8000 0x7980 0x1 0x0 0x0 0x9 0x32 0x3b 0x8000 0x6d00 0x8000 0x2 0x0 0xa 0x13 0x32 0x3b 0x7a00 0x7100 0x8000 0x3 0x0 0x14 0x1d 0x32 0x3b 0x7400 0x7180 0x8000 0x4 0x0 0x1e 0x27 0x32 0x3b 0x7100 0x7200 0x8000 0x5 0x0 0x28 0x31 0x32 0x3b 0x6c80 0x7180 0x8000 0x6 0x0 0x32 0x3b 0x32 0x3b 0x6680 0x7300 0x8000 0x7 0x0 0x0 0x9 0x28 0x31 0x8000 0x6b80 0x7080 0x8 0x0 0xa 0x13 0x28 0x31 0x8000 0x7400 0x8000 0x9 0x0 0x14 0x1d 0x28 0x31 0x7a00 0x7700 0x8000 0xa 0x0 0x1e 0x27 0x28 0x31 0x7600 0x7780 0x8000 0xb 0x0 0x28 0x31 0x28 0x31 0x6f80 0x7980 0x8000 0xc 0x0 0x32 0x3b 0x28 0x31 0x7080 0x7e80 0x8000 0xd 0x0 0x0 0x9 0x14 0x27 0x8000 0x6b00 0x6d00 0xe 0x0 0xa 0x13 0x14 0x27 0x8000 0x7380 0x7480 0xff 0x0 0x14 0x27 0x14 0x27 0x8000 0x8000 0x8000 0x10 0x0 0x28 0x31 0x14 0x27 0x7500 0x8000 0x7e80 0x11 0x0 0x32 0x3b 0x14 0x27 0x7100 0x8000 0x7c80 0x12 0x0 0x0 0x9 0x0 0x9 0x8000 0x6900 0x6500 0x13 0x0 0x0 0x13 0xa 0x13 0x8000 0x7300 0x6f00 0x13 0x0 0xa 0x13 0x0 0x9 0x8000 0x7300 0x6f00 0x14 0x0 0x14 0x27 0xa 0x13 0x7f00 0x8000 0x7900 0x15 0x0 0x14 0x27 0x0 0x9 0x7e80 0x8000 0x7680 0x16 0x0 0x28 0x31 0xa 0x13 0x7380 0x8000 0x7600 0x17 0x0 0x32 0x3b 0xa 0x13 0x7080 0x8000 0x7900 0x18 0x0 0x28 0x31 0x0 0x9 0x7a00 0x8000 0x7580 0x19 0x0 0x32 0x3b 0x0 0x9 0x6f00 0x8000 0x7200>;
			};

			somc,novatek_sharp_1080p_panel {
				qcom,mdss-dsi-panel-name = "sharp novatek 1080p video";
				qcom,mdss-dsi-panel-controller = <0x23>;
				qcom,mdss-dsi-panel-type = "dsi_video_mode";
				qcom,mdss-dsi-panel-destination = "display_1";
				qcom,mdss-dsi-panel-framerate = <0x3c>;
				qcom,mdss-dsi-virtual-channel-id = <0x0>;
				qcom,mdss-dsi-stream = <0x0>;
				qcom,mdss-dsi-panel-width = <0x438>;
				qcom,mdss-dsi-panel-height = <0x780>;
				qcom,mdss-dsi-h-front-porch = <0x80>;
				qcom,mdss-dsi-h-back-porch = <0x4c>;
				qcom,mdss-dsi-h-pulse-width = <0x4>;
				qcom,mdss-dsi-h-sync-skew = <0x0>;
				qcom,mdss-dsi-v-back-porch = <0x5>;
				qcom,mdss-dsi-v-front-porch = <0x2>;
				qcom,mdss-dsi-v-pulse-width = <0x2>;
				qcom,mdss-dsi-h-left-border = <0x0>;
				qcom,mdss-dsi-h-right-border = <0x0>;
				qcom,mdss-dsi-v-top-border = <0x0>;
				qcom,mdss-dsi-v-bottom-border = <0x0>;
				qcom,mdss-dsi-bpp = <0x18>;
				qcom,mdss-dsi-underflow-color = <0x0>;
				qcom,mdss-dsi-border-color = <0x0>;
				somc,mdss-dsi-init-command = [15 01 00 00 00 00 02 ff 01 15 01 00 00 00 00 02 fb 01 15 01 00 00 00 00 02 15 14 15 01 00 00 00 00 02 16 12 15 01 00 00 00 00 02 58 82 15 01 00 00 00 00 02 59 00 15 01 00 00 00 00 02 5a 02 15 01 00 00 00 00 02 5b 00 15 01 00 00 00 00 02 5c 82 15 01 00 00 00 00 02 5d 00 15 01 00 00 00 00 02 5e 02 15 01 00 00 00 00 02 5f 00 15 01 00 00 00 00 02 60 0f 15 01 00 00 00 00 02 6d 22 15 01 00 00 00 00 02 ff 05 15 01 00 00 00 00 02 fb 01 15 01 00 00 00 00 02 a6 04 15 01 00 00 00 00 02 c4 04 15 01 00 00 00 00 02 ff 00 15 01 00 00 00 00 02 ff 01 15 01 00 00 00 00 02 fb 01 15 01 00 00 00 00 02 75 00 15 01 00 00 00 00 02 76 21 15 01 00 00 00 00 02 77 00 15 01 00 00 00 00 02 78 57 15 01 00 00 00 00 02 79 00 15 01 00 00 00 00 02 7a 8a 15 01 00 00 00 00 02 7b 00 15 01 00 00 00 00 02 7c a9 15 01 00 00 00 00 02 7d 00 15 01 00 00 00 00 02 7e c1 15 01 00 00 00 00 02 7f 00 15 01 00 00 00 00 02 80 d6 15 01 00 00 00 00 02 81 00 15 01 00 00 00 00 02 82 e4 15 01 00 00 00 00 02 83 00 15 01 00 00 00 00 02 84 f6 15 01 00 00 00 00 02 85 01 15 01 00 00 00 00 02 86 06 15 01 00 00 00 00 02 87 01 15 01 00 00 00 00 02 88 33 15 01 00 00 00 00 02 89 01 15 01 00 00 00 00 02 8a 59 15 01 00 00 00 00 02 8b 01 15 01 00 00 00 00 02 8c 95 15 01 00 00 00 00 02 8d 01 15 01 00 00 00 00 02 8e c5 15 01 00 00 00 00 02 8f 02 15 01 00 00 00 00 02 90 11 15 01 00 00 00 00 02 91 02 15 01 00 00 00 00 02 92 4d 15 01 00 00 00 00 02 93 02 15 01 00 00 00 00 02 94 4f 15 01 00 00 00 00 02 95 02 15 01 00 00 00 00 02 96 77 15 01 00 00 00 00 02 97 02 15 01 00 00 00 00 02 98 a2 15 01 00 00 00 00 02 99 02 15 01 00 00 00 00 02 9a be 15 01 00 00 00 00 02 9b 02 15 01 00 00 00 00 02 9c e5 15 01 00 00 00 00 02 9d 03 15 01 00 00 00 00 02 9e 04 15 01 00 00 00 00 02 9f 03 15 01 00 00 00 00 02 a0 2c 15 01 00 00 00 00 02 a2 03 15 01 00 00 00 00 02 a3 39 15 01 00 00 00 00 02 a4 03 15 01 00 00 00 00 02 a5 46 15 01 00 00 00 00 02 a6 03 15 01 00 00 00 00 02 a7 55 15 01 00 00 00 00 02 a9 03 15 01 00 00 00 00 02 aa 66 15 01 00 00 00 00 02 ab 03 15 01 00 00 00 00 02 ac 7b 15 01 00 00 00 00 02 ad 03 15 01 00 00 00 00 02 ae 95 15 01 00 00 00 00 02 af 03 15 01 00 00 00 00 02 b0 b4 15 01 00 00 00 00 02 b1 03 15 01 00 00 00 00 02 b2 bb 15 01 00 00 00 00 02 b3 00 15 01 00 00 00 00 02 b4 5b 15 01 00 00 00 00 02 b5 00 15 01 00 00 00 00 02 b6 94 15 01 00 00 00 00 02 b7 00 15 01 00 00 00 00 02 b8 c2 15 01 00 00 00 00 02 b9 00 15 01 00 00 00 00 02 ba de 15 01 00 00 00 00 02 bb 00 15 01 00 00 00 00 02 bc f5 15 01 00 00 00 00 02 bd 01 15 01 00 00 00 00 02 be 09 15 01 00 00 00 00 02 bf 01 15 01 00 00 00 00 02 c0 15 15 01 00 00 00 00 02 c1 01 15 01 00 00 00 00 02 c2 26 15 01 00 00 00 00 02 c3 01 15 01 00 00 00 00 02 c4 34 15 01 00 00 00 00 02 c5 01 15 01 00 00 00 00 02 c6 5c 15 01 00 00 00 00 02 c7 01 15 01 00 00 00 00 02 c8 7c 15 01 00 00 00 00 02 c9 01 15 01 00 00 00 00 02 ca ac 15 01 00 00 00 00 02 cb 01 15 01 00 00 00 00 02 cc d2 15 01 00 00 00 00 02 cd 02 15 01 00 00 00 00 02 ce 0d 15 01 00 00 00 00 02 cf 02 15 01 00 00 00 00 02 d0 3b 15 01 00 00 00 00 02 d1 02 15 01 00 00 00 00 02 d2 3d 15 01 00 00 00 00 02 d3 02 15 01 00 00 00 00 02 d4 73 15 01 00 00 00 00 02 d5 02 15 01 00 00 00 00 02 d6 ad 15 01 00 00 00 00 02 d7 02 15 01 00 00 00 00 02 d8 cf 15 01 00 00 00 00 02 d9 02 15 01 00 00 00 00 02 da fe 15 01 00 00 00 00 02 db 03 15 01 00 00 00 00 02 dc 1c 15 01 00 00 00 00 02 dd 03 15 01 00 00 00 00 02 de 44 15 01 00 00 00 00 02 df 03 15 01 00 00 00 00 02 e0 51 15 01 00 00 00 00 02 e1 03 15 01 00 00 00 00 02 e2 5e 15 01 00 00 00 00 02 e3 03 15 01 00 00 00 00 02 e4 6e 15 01 00 00 00 00 02 e5 03 15 01 00 00 00 00 02 e6 7f 15 01 00 00 00 00 02 e7 03 15 01 00 00 00 00 02 e8 93 15 01 00 00 00 00 02 e9 03 15 01 00 00 00 00 02 ea ac 15 01 00 00 00 00 02 eb 03 15 01 00 00 00 00 02 ec ca 15 01 00 00 00 00 02 ed 03 15 01 00 00 00 00 02 ee d1 15 01 00 00 00 00 02 ef 00 15 01 00 00 00 00 02 f0 14 15 01 00 00 00 00 02 f1 00 15 01 00 00 00 00 02 f2 50 15 01 00 00 00 00 02 f3 00 15 01 00 00 00 00 02 f4 84 15 01 00 00 00 00 02 f5 00 15 01 00 00 00 00 02 f6 a4 15 01 00 00 00 00 02 f7 00 15 01 00 00 00 00 02 f8 b9 15 01 00 00 00 00 02 f9 00 15 01 00 00 00 00 02 fa d2 15 01 00 00 00 00 02 ff 02 15 01 00 00 00 00 02 fb 01 15 01 00 00 00 00 02 00 00 15 01 00 00 00 00 02 01 e1 15 01 00 00 00 00 02 02 00 15 01 00 00 00 00 02 03 f1 15 01 00 00 00 00 02 04 01 15 01 00 00 00 00 02 05 02 15 01 00 00 00 00 02 06 01 15 01 00 00 00 00 02 07 31 15 01 00 00 00 00 02 08 01 15 01 00 00 00 00 02 09 56 15 01 00 00 00 00 02 0a 01 15 01 00 00 00 00 02 0b 93 15 01 00 00 00 00 02 0c 01 15 01 00 00 00 00 02 0d c4 15 01 00 00 00 00 02 0e 02 15 01 00 00 00 00 02 0f 0f 15 01 00 00 00 00 02 10 02 15 01 00 00 00 00 02 11 4b 15 01 00 00 00 00 02 12 02 15 01 00 00 00 00 02 13 4c 15 01 00 00 00 00 02 14 02 15 01 00 00 00 00 02 15 75 15 01 00 00 00 00 02 16 02 15 01 00 00 00 00 02 17 a0 15 01 00 00 00 00 02 18 02 15 01 00 00 00 00 02 19 bb 15 01 00 00 00 00 02 1a 02 15 01 00 00 00 00 02 1b e0 15 01 00 00 00 00 02 1c 02 15 01 00 00 00 00 02 1d ff 15 01 00 00 00 00 02 1e 03 15 01 00 00 00 00 02 1f 27 15 01 00 00 00 00 02 20 03 15 01 00 00 00 00 02 21 33 15 01 00 00 00 00 02 22 03 15 01 00 00 00 00 02 23 41 15 01 00 00 00 00 02 24 03 15 01 00 00 00 00 02 25 50 15 01 00 00 00 00 02 26 03 15 01 00 00 00 00 02 27 61 15 01 00 00 00 00 02 28 03 15 01 00 00 00 00 02 29 76 15 01 00 00 00 00 02 2a 03 15 01 00 00 00 00 02 2b 91 15 01 00 00 00 00 02 2d 03 15 01 00 00 00 00 02 2f b3 15 01 00 00 00 00 02 30 03 15 01 00 00 00 00 02 31 bb 15 01 00 00 00 00 02 32 00 15 01 00 00 00 00 02 33 4e 15 01 00 00 00 00 02 34 00 15 01 00 00 00 00 02 35 8f 15 01 00 00 00 00 02 36 00 15 01 00 00 00 00 02 37 be 15 01 00 00 00 00 02 38 00 15 01 00 00 00 00 02 39 db 15 01 00 00 00 00 02 3a 00 15 01 00 00 00 00 02 3b ef 15 01 00 00 00 00 02 3d 01 15 01 00 00 00 00 02 3f 06 15 01 00 00 00 00 02 40 01 15 01 00 00 00 00 02 41 13 15 01 00 00 00 00 02 42 01 15 01 00 00 00 00 02 43 22 15 01 00 00 00 00 02 44 01 15 01 00 00 00 00 02 45 31 15 01 00 00 00 00 02 46 01 15 01 00 00 00 00 02 47 5b 15 01 00 00 00 00 02 48 01 15 01 00 00 00 00 02 49 7b 15 01 00 00 00 00 02 4a 01 15 01 00 00 00 00 02 4b ab 15 01 00 00 00 00 02 4c 01 15 01 00 00 00 00 02 4d d1 15 01 00 00 00 00 02 4e 02 15 01 00 00 00 00 02 4f 0b 15 01 00 00 00 00 02 50 02 15 01 00 00 00 00 02 51 39 15 01 00 00 00 00 02 52 02 15 01 00 00 00 00 02 53 3a 15 01 00 00 00 00 02 54 02 15 01 00 00 00 00 02 55 71 15 01 00 00 00 00 02 56 02 15 01 00 00 00 00 02 58 aa 15 01 00 00 00 00 02 59 02 15 01 00 00 00 00 02 5a cc 15 01 00 00 00 00 02 5b 02 15 01 00 00 00 00 02 5c fa 15 01 00 00 00 00 02 5d 03 15 01 00 00 00 00 02 5e 17 15 01 00 00 00 00 02 5f 03 15 01 00 00 00 00 02 60 3f 15 01 00 00 00 00 02 61 03 15 01 00 00 00 00 02 62 4b 15 01 00 00 00 00 02 63 03 15 01 00 00 00 00 02 64 59 15 01 00 00 00 00 02 65 03 15 01 00 00 00 00 02 66 68 15 01 00 00 00 00 02 67 03 15 01 00 00 00 00 02 68 7a 15 01 00 00 00 00 02 69 03 15 01 00 00 00 00 02 6a 8e 15 01 00 00 00 00 02 6b 03 15 01 00 00 00 00 02 6c a8 15 01 00 00 00 00 02 6d 03 15 01 00 00 00 00 02 6e c9 15 01 00 00 00 00 02 6f 03 15 01 00 00 00 00 02 70 d1 15 01 00 00 00 00 02 71 00 15 01 00 00 00 00 02 72 00 15 01 00 00 00 00 02 73 00 15 01 00 00 00 00 02 74 38 15 01 00 00 00 00 02 75 00 15 01 00 00 00 00 02 76 6c 15 01 00 00 00 00 02 77 00 15 01 00 00 00 00 02 78 8f 15 01 00 00 00 00 02 79 00 15 01 00 00 00 00 02 7a aa 15 01 00 00 00 00 02 7b 00 15 01 00 00 00 00 02 7c bf 15 01 00 00 00 00 02 7d 00 15 01 00 00 00 00 02 7e d5 15 01 00 00 00 00 02 7f 00 15 01 00 00 00 00 02 80 e2 15 01 00 00 00 00 02 81 00 15 01 00 00 00 00 02 82 f3 15 01 00 00 00 00 02 83 01 15 01 00 00 00 00 02 84 27 15 01 00 00 00 00 02 85 01 15 01 00 00 00 00 02 86 4e 15 01 00 00 00 00 02 87 01 15 01 00 00 00 00 02 88 8d 15 01 00 00 00 00 02 89 01 15 01 00 00 00 00 02 8a c0 15 01 00 00 00 00 02 8b 02 15 01 00 00 00 00 02 8c 0d 15 01 00 00 00 00 02 8d 02 15 01 00 00 00 00 02 8e 4b 15 01 00 00 00 00 02 8f 02 15 01 00 00 00 00 02 90 4c 15 01 00 00 00 00 02 91 02 15 01 00 00 00 00 02 92 76 15 01 00 00 00 00 02 93 02 15 01 00 00 00 00 02 94 a1 15 01 00 00 00 00 02 95 02 15 01 00 00 00 00 02 96 bd 15 01 00 00 00 00 02 97 02 15 01 00 00 00 00 02 98 e4 15 01 00 00 00 00 02 99 03 15 01 00 00 00 00 02 9a 03 15 01 00 00 00 00 02 9b 03 15 01 00 00 00 00 02 9c 2d 15 01 00 00 00 00 02 9d 03 15 01 00 00 00 00 02 9e 39 15 01 00 00 00 00 02 9f 03 15 01 00 00 00 00 02 a0 46 15 01 00 00 00 00 02 a2 03 15 01 00 00 00 00 02 a3 56 15 01 00 00 00 00 02 a4 03 15 01 00 00 00 00 02 a5 68 15 01 00 00 00 00 02 a6 03 15 01 00 00 00 00 02 a7 7f 15 01 00 00 00 00 02 a9 03 15 01 00 00 00 00 02 aa 97 15 01 00 00 00 00 02 ab 03 15 01 00 00 00 00 02 ac b5 15 01 00 00 00 00 02 ad 03 15 01 00 00 00 00 02 ae bb 15 01 00 00 00 00 02 af 00 15 01 00 00 00 00 02 b0 39 15 01 00 00 00 00 02 b1 00 15 01 00 00 00 00 02 b2 76 15 01 00 00 00 00 02 b3 00 15 01 00 00 00 00 02 b4 a6 15 01 00 00 00 00 02 b5 00 15 01 00 00 00 00 02 b6 c6 15 01 00 00 00 00 02 b7 00 15 01 00 00 00 00 02 b8 df 15 01 00 00 00 00 02 b9 00 15 01 00 00 00 00 02 ba f2 15 01 00 00 00 00 02 bb 01 15 01 00 00 00 00 02 bc 07 15 01 00 00 00 00 02 bd 01 15 01 00 00 00 00 02 be 13 15 01 00 00 00 00 02 bf 01 15 01 00 00 00 00 02 c0 22 15 01 00 00 00 00 02 c1 01 15 01 00 00 00 00 02 c2 50 15 01 00 00 00 00 02 c3 01 15 01 00 00 00 00 02 c4 72 15 01 00 00 00 00 02 c5 01 15 01 00 00 00 00 02 c6 a5 15 01 00 00 00 00 02 c7 01 15 01 00 00 00 00 02 c8 cd 15 01 00 00 00 00 02 c9 02 15 01 00 00 00 00 02 ca 09 15 01 00 00 00 00 02 cb 02 15 01 00 00 00 00 02 cc 39 15 01 00 00 00 00 02 cd 02 15 01 00 00 00 00 02 ce 3a 15 01 00 00 00 00 02 cf 02 15 01 00 00 00 00 02 d0 72 15 01 00 00 00 00 02 d1 02 15 01 00 00 00 00 02 d2 ac 15 01 00 00 00 00 02 d3 02 15 01 00 00 00 00 02 d4 cf 15 01 00 00 00 00 02 d5 02 15 01 00 00 00 00 02 d6 fe 15 01 00 00 00 00 02 d7 03 15 01 00 00 00 00 02 d8 1c 15 01 00 00 00 00 02 d9 03 15 01 00 00 00 00 02 da 45 15 01 00 00 00 00 02 db 03 15 01 00 00 00 00 02 dc 51 15 01 00 00 00 00 02 dd 03 15 01 00 00 00 00 02 de 5f 15 01 00 00 00 00 02 df 03 15 01 00 00 00 00 02 e0 6f 15 01 00 00 00 00 02 e1 03 15 01 00 00 00 00 02 e2 81 15 01 00 00 00 00 02 e3 03 15 01 00 00 00 00 02 e4 97 15 01 00 00 00 00 02 e5 03 15 01 00 00 00 00 02 e6 ae 15 01 00 00 00 00 02 e7 03 15 01 00 00 00 00 02 e8 cb 15 01 00 00 00 00 02 e9 03 15 01 00 00 00 00 02 ea d1 15 01 00 00 00 00 02 ff 00 05 01 00 00 96 00 01 11 15 01 00 00 00 00 02 d3 07 15 01 00 00 00 00 02 d4 02];
				qcom,mdss-dsi-on-command = <0x5010000 0x129>;
				qcom,mdss-dsi-off-command = <0x5010000 0x14000128 0x5010000 0x64000110>;
				qcom,mdss-dsi-on-command-state = "dsi_lp_mode";
				qcom,mdss-dsi-off-command-state = "dsi_hs_mode";
				somc,mdss-dsi-cabc-early-on-command = <0x39010000 0x351 0xfff1501 0x0 0x2532415 0x1000000 0x25502>;
				somc,mdss-dsi-cabc-late-off-command = <0x39010000 0x351 0x1501 0x0 0x2550015 0x1000000 0x25320>;
				somc,mdss-dsi-cabc-enabled = <0x0>;
				qcom,mdss-dsi-h-sync-pulse = <0x1>;
				qcom,mdss-dsi-traffic-mode = "non_burst_sync_event";
				qcom,mdss-dsi-bllp-eof-power-mode;
				qcom,mdss-dsi-bllp-power-mode;
				qcom,mdss-dsi-lane-0-state;
				qcom,mdss-dsi-lane-1-state;
				qcom,mdss-dsi-lane-2-state;
				qcom,mdss-dsi-lane-3-state;
				qcom,mdss-dsi-panel-timings = <0xe6382600 0x686c2a3a 0x2c030400>;
				qcom,mdss-dsi-lp11-init;
				qcom,mdss-dsi-t-clk-post = <0x2>;
				qcom,mdss-dsi-t-clk-pre = <0x2b>;
				qcom,mdss-dsi-bl-min-level = <0x1>;
				qcom,mdss-dsi-bl-max-level = <0xff>;
				qcom,mdss-brightness-max-level = <0xff>;
				qcom,mdss-dsi-dma-trigger = "trigger_sw";
				qcom,mdss-dsi-mdp-trigger = "none";
				qcom,mdss-dsi-bl-pmic-control-type = "bl_ctrl_wled";
				qcom,mdss-dsi-pan-enable-dynamic-fps;
				qcom,mdss-dsi-pan-fps-update = "dfps_suspend_resume_mode";
				qcom,cont-splash-enabled;
				qcom,mdss-dsi-tx-eot-append;
				somc,driver-ic = <0x1>;
				somc,mul-channel-scaling = <0x3>;
				somc,mdss-phy-size-mm = <0x40 0x72>;
				somc,mdss-dsi-lane-config = [00 c2 ef 00 00 00 00 01 75 00 c2 ef 00 00 00 00 01 75 00 c2 ef 00 00 00 00 01 75 00 c2 ef 00 00 00 00 01 75 00 02 45 00 00 00 00 01 97];
				somc,mdss-dsi-disp-on-in-hs = <0x1>;
				somc,lcd-id = <0x1>;
				somc,lcd-id-adc = <0x12dc20 0x154938>;
				somc,disp-en-on-pre = <0x19>;
				somc,pw-on-rst-seq = <0x0 0x3c 0x1 0xa>;
				somc,disp-en-off-post = <0x32>;
				somc,pw-off-rst-b-seq = <0x0 0xa>;
				somc,mdss-dsi-pre-uv-command = [15 01 00 00 00 00 02 ff 00];
				somc,mdss-dsi-uv-command = <0x6010000 0x1da 0x6010000 0x1db>;
				somc,mdss-dsi-uv-param-type = <0x2>;
				somc,mdss-dsi-pcc-table-size = <0x49>;
				somc,mdss-dsi-pcc-table = <0x0 0x1 0x10 0x13 0x28 0x2b 0x8000 0x7400 0x8000 0x0 0x2 0x14 0x17 0x28 0x2b 0x7a80 0x7400 0x7e00 0x0 0x3 0x18 0x1b 0x28 0x2b 0x7480 0x7380 0x8000 0x0 0x4 0x1c 0x1f 0x28 0x2b 0x7280 0x7380 0x8000 0x0 0x5 0x20 0x23 0x28 0x2b 0x6e00 0x7400 0x8000 0x0 0x6 0xc 0xf 0x24 0x27 0x7f80 0x7200 0x7c00 0x0 0x7 0x10 0x13 0x24 0x27 0x8000 0x7400 0x7d80 0x0 0x8 0x14 0x17 0x24 0x27 0x7d00 0x7700 0x7e00 0x0 0x9 0x18 0x1b 0x24 0x27 0x7700 0x7600 0x8000 0x0 0xa 0x1c 0x1f 0x24 0x27 0x7380 0x7500 0x7c00 0x0 0xb 0x20 0x23 0x24 0x27 0x6f00 0x7500 0x7e80 0x0 0xc 0xc 0xf 0x20 0x23 0x7f80 0x7200 0x7900 0x0 0xd 0x10 0x13 0x20 0x23 0x8000 0x7400 0x7b00 0x0 0xe 0x14 0x17 0x20 0x23 0x7a80 0x7400 0x7b00 0x0 0xf 0x18 0x1b 0x20 0x23 0x7800 0x7700 0x7e80 0x0 0x10 0x1c 0x1f 0x20 0x23 0x7780 0x7900 0x7f80 0x0 0x11 0x20 0x23 0x20 0x23 0x7300 0x7900 0x7f00 0x0 0x12 0x24 0x27 0x20 0x23 0x7100 0x7980 0x8000 0x0 0x13 0xc 0xf 0x1c 0x1f 0x7f80 0x7200 0x7700 0x0 0x14 0x10 0x13 0x1c 0x1f 0x7c00 0x7000 0x7580 0x0 0x15 0x14 0x17 0x1c 0x1f 0x7f80 0x7900 0x7e00 0x0 0x16 0x18 0x1b 0x1c 0x1f 0x7c00 0x7a00 0x7d80 0x0 0x17 0x1c 0x1f 0x1c 0x1f 0x7900 0x7a00 0x7e00 0x0 0x18 0x20 0x23 0x1c 0x1f 0x7600 0x7c80 0x8000 0x0 0x19 0x24 0x27 0x1c 0x1f 0x7300 0x7c00 0x7e80 0x0 0x1a 0xc 0xf 0x18 0x1b 0x8000 0x7200 0x7300 0x0 0x1b 0x10 0x13 0x18 0x1b 0x7e80 0x7200 0x7500 0x0 0x1c 0x14 0x17 0x18 0x1b 0x7f00 0x7900 0x7b80 0x0 0x1d 0x18 0x1b 0x18 0x1b 0x7f00 0x7d00 0x7e00 0x0 0x1e 0x1c 0x1f 0x18 0x1b 0x7d00 0x7d80 0x8000 0x0 0x1f 0x20 0x23 0x18 0x1b 0x7900 0x7f00 0x8000 0x0 0x20 0x24 0x27 0x18 0x1b 0x7780 0x8000 0x8000 0x0 0x21 0x10 0x13 0x14 0x17 0x7f80 0x7380 0x7200 0x0 0x22 0x14 0x17 0x14 0x17 0x7f00 0x7900 0x7900 0x0 0x23 0x18 0x1b 0x14 0x17 0x7f00 0x7d00 0x7b80 0xff 0x0 0x1c 0x1f 0x14 0x17 0x8000 0x8000 0x8000 0x0 0x24 0x20 0x23 0x14 0x17 0x7a00 0x8000 0x7e80 0x0 0x25 0x24 0x27 0x14 0x17 0x7780 0x8000 0x7d80 0x0 0x26 0x10 0x13 0x10 0x13 0x8000 0x7400 0x7000 0x0 0x27 0x14 0x17 0x10 0x13 0x7f80 0x7900 0x7680 0x0 0x28 0x18 0x1b 0x10 0x13 0x8000 0x7d80 0x7980 0x0 0x29 0x1c 0x1f 0x10 0x13 0x8000 0x8000 0x7c00 0x0 0x2a 0x20 0x23 0x10 0x13 0x7a00 0x8000 0x7c00 0x0 0x2b 0x10 0x13 0xc 0xf 0x7f80 0x7480 0x6f00 0x0 0x2c 0x14 0x17 0xc 0xf 0x7f80 0x7900 0x7400 0x0 0x2d 0x18 0x1b 0xc 0xf 0x7f80 0x7d80 0x7680 0x0 0x2e 0x1c 0x1f 0xc 0xf 0x8000 0x8000 0x7980 0x1 0x0 0x0 0x9 0x32 0x3b 0x8000 0x6d00 0x8000 0x2 0x0 0xa 0x13 0x32 0x3b 0x7a00 0x7100 0x8000 0x3 0x0 0x14 0x1d 0x32 0x3b 0x7400 0x7180 0x8000 0x4 0x0 0x1e 0x27 0x32 0x3b 0x7100 0x7200 0x8000 0x5 0x0 0x28 0x31 0x32 0x3b 0x6c80 0x7180 0x8000 0x6 0x0 0x32 0x3b 0x32 0x3b 0x6680 0x7300 0x8000 0x7 0x0 0x0 0x9 0x28 0x31 0x8000 0x6b80 0x7080 0x8 0x0 0xa 0x13 0x28 0x31 0x8000 0x7400 0x8000 0x9 0x0 0x14 0x1d 0x28 0x31 0x7a00 0x7700 0x8000 0xa 0x0 0x1e 0x27 0x28 0x31 0x7600 0x7780 0x8000 0xb 0x0 0x28 0x31 0x28 0x31 0x6f80 0x7980 0x8000 0xc 0x0 0x32 0x3b 0x28 0x31 0x7080 0x7e80 0x8000 0xd 0x0 0x0 0x9 0x14 0x27 0x8000 0x6b00 0x6d00 0xe 0x0 0xa 0x13 0x14 0x27 0x8000 0x7380 0x7480 0xff 0x0 0x14 0x27 0x14 0x27 0x8000 0x8000 0x8000 0x10 0x0 0x28 0x31 0x14 0x27 0x7500 0x8000 0x7e80 0x11 0x0 0x32 0x3b 0x14 0x27 0x7100 0x8000 0x7c80 0x12 0x0 0x0 0x9 0x0 0x9 0x8000 0x6900 0x6500 0x13 0x0 0x0 0x13 0xa 0x13 0x8000 0x7300 0x6f00 0x13 0x0 0xa 0x13 0x0 0x9 0x8000 0x7300 0x6f00 0x14 0x0 0x14 0x27 0xa 0x13 0x7f00 0x8000 0x7900 0x15 0x0 0x14 0x27 0x0 0x9 0x7e80 0x8000 0x7680 0x16 0x0 0x28 0x31 0xa 0x13 0x7380 0x8000 0x7600 0x17 0x0 0x32 0x3b 0xa 0x13 0x7080 0x8000 0x7900 0x18 0x0 0x28 0x31 0x0 0x9 0x7a00 0x8000 0x7580 0x19 0x0 0x32 0x3b 0x0 0x9 0x6f00 0x8000 0x7200>;
			};

			somc,novatek_auo_1080p_panel {
				qcom,mdss-dsi-panel-name = "auo novatek 1080p video";
				qcom,mdss-dsi-panel-controller = <0x23>;
				qcom,mdss-dsi-panel-type = "dsi_video_mode";
				qcom,mdss-dsi-panel-destination = "display_1";
				qcom,mdss-dsi-panel-framerate = <0x3c>;
				qcom,mdss-dsi-virtual-channel-id = <0x0>;
				qcom,mdss-dsi-stream = <0x0>;
				qcom,mdss-dsi-panel-width = <0x438>;
				qcom,mdss-dsi-panel-height = <0x780>;
				qcom,mdss-dsi-h-front-porch = <0x68>;
				qcom,mdss-dsi-h-back-porch = <0x38>;
				qcom,mdss-dsi-h-pulse-width = <0x14>;
				qcom,mdss-dsi-h-sync-skew = <0x0>;
				qcom,mdss-dsi-v-back-porch = <0x2e>;
				qcom,mdss-dsi-v-front-porch = <0x6>;
				qcom,mdss-dsi-v-pulse-width = <0x2>;
				qcom,mdss-dsi-h-left-border = <0x0>;
				qcom,mdss-dsi-h-right-border = <0x0>;
				qcom,mdss-dsi-v-top-border = <0x0>;
				qcom,mdss-dsi-v-bottom-border = <0x0>;
				qcom,mdss-dsi-bpp = <0x18>;
				qcom,mdss-dsi-underflow-color = <0x0>;
				qcom,mdss-dsi-border-color = <0x0>;
				somc,mdss-dsi-init-command = [15 01 00 00 00 00 02 ff 05 15 01 00 00 00 00 02 fb 01 15 01 00 00 00 00 02 93 06 15 01 00 00 00 00 02 94 30 15 01 00 00 00 00 02 ff 00 15 01 00 00 00 00 02 ff 01 15 01 00 00 00 00 02 01 55 15 01 00 00 00 00 02 15 0f 15 01 00 00 00 00 02 16 0f 15 01 00 00 00 00 02 1b 1b 15 01 00 00 00 00 02 1c f7 15 01 00 00 00 00 02 60 0f 15 01 00 00 00 00 02 58 82 15 01 00 00 00 00 02 59 00 15 01 00 00 00 00 02 5a 02 15 01 00 00 00 00 02 5b 00 15 01 00 00 00 00 02 5c 82 15 01 00 00 00 00 02 5d 80 15 01 00 00 00 00 02 5e 02 15 01 00 00 00 00 02 5f 00 15 01 00 00 00 00 02 66 01 15 01 00 00 00 00 02 fb 01 15 01 00 00 00 00 02 ff 05 15 01 00 00 00 00 02 54 75 15 01 00 00 00 00 02 85 05 15 01 00 00 00 00 02 a6 04 15 01 00 00 00 00 02 fb 01 15 01 00 00 00 00 02 ff ff 15 01 00 00 00 00 02 4f 03 15 01 00 00 00 00 02 fb 01 15 01 00 00 00 00 02 ff 00 15 01 00 00 00 00 02 35 01 15 01 00 00 00 00 02 d3 30 15 01 00 00 00 00 02 d4 06 05 01 00 00 64 00 01 11];
				qcom,mdss-dsi-on-command = <0x5010000 0x64000129>;
				qcom,mdss-dsi-off-command = <0x5010000 0x14000128 0x5010000 0x64000110>;
				qcom,mdss-dsi-on-command-state = "dsi_lp_mode";
				qcom,mdss-dsi-off-command-state = "dsi_hs_mode";
				qcom,mdss-dsi-h-sync-pulse = <0x1>;
				qcom,mdss-dsi-traffic-mode = "non_burst_sync_event";
				qcom,mdss-dsi-bllp-eof-power-mode;
				qcom,mdss-dsi-bllp-power-mode;
				qcom,mdss-dsi-lane-0-state;
				qcom,mdss-dsi-lane-1-state;
				qcom,mdss-dsi-lane-2-state;
				qcom,mdss-dsi-lane-3-state;
				qcom,mdss-dsi-panel-timings = <0xe6382600 0x686c2a3c 0x2c030400>;
				qcom,mdss-dsi-lp11-init;
				qcom,mdss-dsi-t-clk-post = <0x2>;
				qcom,mdss-dsi-t-clk-pre = <0x2b>;
				qcom,mdss-dsi-bl-min-level = <0x1>;
				qcom,mdss-dsi-bl-max-level = <0xff>;
				qcom,mdss-brightness-max-level = <0xff>;
				qcom,mdss-dsi-dma-trigger = "trigger_sw";
				qcom,mdss-dsi-mdp-trigger = "none";
				qcom,mdss-dsi-bl-pmic-control-type = "bl_ctrl_wled";
				qcom,mdss-dsi-pan-enable-dynamic-fps;
				qcom,mdss-dsi-pan-fps-update = "dfps_suspend_resume_mode";
				qcom,cont-splash-enabled;
				qcom,mdss-dsi-tx-eot-append;
				somc,driver-ic = <0x1>;
				somc,mul-channel-scaling = <0x3>;
				somc,mdss-phy-size-mm = <0x40 0x72>;
				somc,mdss-dsi-lane-config = [00 c2 ef 00 00 00 00 01 75 00 c2 ef 00 00 00 00 01 75 00 c2 ef 00 00 00 00 01 75 00 c2 ef 00 00 00 00 01 75 00 02 45 00 00 00 00 01 97];
				somc,mdss-dsi-disp-on-in-hs = <0x1>;
				somc,lcd-id = <0x1>;
				somc,lcd-id-adc = <0x15aae0 0x185290>;
				somc,disp-en-on-post = <0x14>;
				somc,disp-en-off-post = <0x46>;
				somc,pw-on-rst-seq = <0x1 0xa>;
				somc,pw-off-rst-seq = <0x0 0x0>;
				somc,mdss-dsi-pre-uv-command = [15 01 00 00 00 00 02 ff 00];
				somc,mdss-dsi-uv-command = <0x6010000 0x1da 0x6010000 0x1dc>;
				somc,mdss-dsi-uv-param-type = <0x2>;
				somc,mdss-dsi-pcc-table-size = <0x49>;
				somc,mdss-dsi-pcc-table = <0x0 0x1 0x10 0x13 0x28 0x2b 0x8000 0x7400 0x8000 0x0 0x2 0x14 0x17 0x28 0x2b 0x7a80 0x7400 0x7e00 0x0 0x3 0x18 0x1b 0x28 0x2b 0x7480 0x7380 0x8000 0x0 0x4 0x1c 0x1f 0x28 0x2b 0x7280 0x7380 0x8000 0x0 0x5 0x20 0x23 0x28 0x2b 0x6e00 0x7400 0x8000 0x0 0x6 0xc 0xf 0x24 0x27 0x7f80 0x7200 0x7c00 0x0 0x7 0x10 0x13 0x24 0x27 0x8000 0x7400 0x7d80 0x0 0x8 0x14 0x17 0x24 0x27 0x7d00 0x7700 0x7e00 0x0 0x9 0x18 0x1b 0x24 0x27 0x7700 0x7600 0x8000 0x0 0xa 0x1c 0x1f 0x24 0x27 0x7380 0x7500 0x7c00 0x0 0xb 0x20 0x23 0x24 0x27 0x6f00 0x7500 0x7e80 0x0 0xc 0xc 0xf 0x20 0x23 0x7f80 0x7200 0x7900 0x0 0xd 0x10 0x13 0x20 0x23 0x8000 0x7400 0x7b00 0x0 0xe 0x14 0x17 0x20 0x23 0x7a80 0x7400 0x7b00 0x0 0xf 0x18 0x1b 0x20 0x23 0x7800 0x7700 0x7e80 0x0 0x10 0x1c 0x1f 0x20 0x23 0x7780 0x7900 0x7f80 0x0 0x11 0x20 0x23 0x20 0x23 0x7300 0x7900 0x7f00 0x0 0x12 0x24 0x27 0x20 0x23 0x7100 0x7980 0x8000 0x0 0x13 0xc 0xf 0x1c 0x1f 0x7f80 0x7200 0x7700 0x0 0x14 0x10 0x13 0x1c 0x1f 0x7c00 0x7000 0x7580 0x0 0x15 0x14 0x17 0x1c 0x1f 0x7f80 0x7900 0x7e00 0x0 0x16 0x18 0x1b 0x1c 0x1f 0x7c00 0x7a00 0x7d80 0x0 0x17 0x1c 0x1f 0x1c 0x1f 0x7900 0x7a00 0x7e00 0x0 0x18 0x20 0x23 0x1c 0x1f 0x7600 0x7c80 0x8000 0x0 0x19 0x24 0x27 0x1c 0x1f 0x7300 0x7c00 0x7e80 0x0 0x1a 0xc 0xf 0x18 0x1b 0x8000 0x7200 0x7300 0x0 0x1b 0x10 0x13 0x18 0x1b 0x7e80 0x7200 0x7500 0x0 0x1c 0x14 0x17 0x18 0x1b 0x7f00 0x7900 0x7b80 0x0 0x1d 0x18 0x1b 0x18 0x1b 0x7f00 0x7d00 0x7e00 0x0 0x1e 0x1c 0x1f 0x18 0x1b 0x7d00 0x7d80 0x8000 0x0 0x1f 0x20 0x23 0x18 0x1b 0x7900 0x7f00 0x8000 0x0 0x20 0x24 0x27 0x18 0x1b 0x7780 0x8000 0x8000 0x0 0x21 0x10 0x13 0x14 0x17 0x7f80 0x7380 0x7200 0x0 0x22 0x14 0x17 0x14 0x17 0x7f00 0x7900 0x7900 0x0 0x23 0x18 0x1b 0x14 0x17 0x7f00 0x7d00 0x7b80 0xff 0x0 0x1c 0x1f 0x14 0x17 0x8000 0x8000 0x8000 0x0 0x24 0x20 0x23 0x14 0x17 0x7a00 0x8000 0x7e80 0x0 0x25 0x24 0x27 0x14 0x17 0x7780 0x8000 0x7d80 0x0 0x26 0x10 0x13 0x10 0x13 0x8000 0x7400 0x7000 0x0 0x27 0x14 0x17 0x10 0x13 0x7f80 0x7900 0x7680 0x0 0x28 0x18 0x1b 0x10 0x13 0x8000 0x7d80 0x7980 0x0 0x29 0x1c 0x1f 0x10 0x13 0x8000 0x8000 0x7c00 0x0 0x2a 0x20 0x23 0x10 0x13 0x7a00 0x8000 0x7c00 0x0 0x2b 0x10 0x13 0xc 0xf 0x7f80 0x7480 0x6f00 0x0 0x2c 0x14 0x17 0xc 0xf 0x7f80 0x7900 0x7400 0x0 0x2d 0x18 0x1b 0xc 0xf 0x7f80 0x7d80 0x7680 0x0 0x2e 0x1c 0x1f 0xc 0xf 0x8000 0x8000 0x7980 0x1 0x0 0x0 0x9 0x32 0x3b 0x8000 0x6d00 0x8000 0x2 0x0 0xa 0x13 0x32 0x3b 0x7a00 0x7100 0x8000 0x3 0x0 0x14 0x1d 0x32 0x3b 0x7400 0x7180 0x8000 0x4 0x0 0x1e 0x27 0x32 0x3b 0x7100 0x7200 0x8000 0x5 0x0 0x28 0x31 0x32 0x3b 0x6c80 0x7180 0x8000 0x6 0x0 0x32 0x3b 0x32 0x3b 0x6680 0x7300 0x8000 0x7 0x0 0x0 0x9 0x28 0x31 0x8000 0x6b80 0x7080 0x8 0x0 0xa 0x13 0x28 0x31 0x8000 0x7400 0x8000 0x9 0x0 0x14 0x1d 0x28 0x31 0x7a00 0x7700 0x8000 0xa 0x0 0x1e 0x27 0x28 0x31 0x7600 0x7780 0x8000 0xb 0x0 0x28 0x31 0x28 0x31 0x6f80 0x7980 0x8000 0xc 0x0 0x32 0x3b 0x28 0x31 0x7080 0x7e80 0x8000 0xd 0x0 0x0 0x9 0x14 0x27 0x8000 0x6b00 0x6d00 0xe 0x0 0xa 0x13 0x14 0x27 0x8000 0x7380 0x7480 0xff 0x0 0x14 0x27 0x14 0x27 0x8000 0x8000 0x8000 0x10 0x0 0x28 0x31 0x14 0x27 0x7500 0x8000 0x7e80 0x11 0x0 0x32 0x3b 0x14 0x27 0x7100 0x8000 0x7c80 0x12 0x0 0x0 0x9 0x0 0x9 0x8000 0x6900 0x6500 0x13 0x0 0x0 0x13 0xa 0x13 0x8000 0x7300 0x6f00 0x13 0x0 0xa 0x13 0x0 0x9 0x8000 0x7300 0x6f00 0x14 0x0 0x14 0x27 0xa 0x13 0x7f00 0x8000 0x7900 0x15 0x0 0x14 0x27 0x0 0x9 0x7e80 0x8000 0x7680 0x16 0x0 0x28 0x31 0xa 0x13 0x7380 0x8000 0x7600 0x17 0x0 0x32 0x3b 0xa 0x13 0x7080 0x8000 0x7900 0x18 0x0 0x28 0x31 0x0 0x9 0x7a00 0x8000 0x7580 0x19 0x0 0x32 0x3b 0x0 0x9 0x6f00 0x8000 0x7200>;
			};

			somc,default_panel_0 {
				qcom,mdss-dsi-panel-name = "default renesas video";
				qcom,mdss-dsi-panel-controller = <0x23>;
				qcom,mdss-dsi-panel-type = "dsi_video_mode";
				qcom,mdss-dsi-panel-destination = "display_1";
				qcom,mdss-dsi-panel-framerate = <0x3c>;
				qcom,mdss-dsi-virtual-channel-id = <0x0>;
				qcom,mdss-dsi-stream = <0x0>;
				qcom,mdss-dsi-panel-width = <0x438>;
				qcom,mdss-dsi-panel-height = <0x780>;
				qcom,mdss-dsi-h-front-porch = <0x80>;
				qcom,mdss-dsi-h-back-porch = <0x4c>;
				qcom,mdss-dsi-h-pulse-width = <0x4>;
				qcom,mdss-dsi-h-sync-skew = <0x0>;
				qcom,mdss-dsi-v-back-porch = <0x3>;
				qcom,mdss-dsi-v-front-porch = <0x4>;
				qcom,mdss-dsi-v-pulse-width = <0x2>;
				qcom,mdss-dsi-h-left-border = <0x0>;
				qcom,mdss-dsi-h-right-border = <0x0>;
				qcom,mdss-dsi-v-top-border = <0x0>;
				qcom,mdss-dsi-v-bottom-border = <0x0>;
				qcom,mdss-dsi-bpp = <0x18>;
				qcom,mdss-dsi-underflow-color = <0x0>;
				qcom,mdss-dsi-border-color = <0x0>;
				somc,mdss-dsi-init-command = <0x23010000 0x2b0 0x4230100 0x2 0x2301 0x0 0x2000023 0x1000000 0x2d601 0x29010000 0x3c0 0xf0f2901 0x0 0x3ec0010 0x29010000 0x19c7 0x519222b 0x38514150 0x5c646b74 0xf232b32 0x3f524455 0x61697077 0x29010000 0x19c8 0x318212b 0x3851424f 0x5d656c74 0xd222a32 0x3e524154 0x5d666d77 0x29010000 0x19c9 0x151e28 0x36504250 0x5e666d74 0xa1f272f 0x3d514155 0x5e676e77 0x5010000 0x111>;
				qcom,mdss-dsi-on-command = <0x5010000 0x129>;
				qcom,mdss-dsi-off-command = <0x5010000 0x14000128 0x5010000 0x6e000110>;
				qcom,mdss-dsi-on-command-state = "dsi_lp_mode";
				qcom,mdss-dsi-off-command-state = "dsi_hs_mode";
				somc,mdss-dsi-cabc-early-on-command = <0x39010000 0x351 0xfff1501 0x0 0x2532415 0x1000000 0x25502>;
				somc,mdss-dsi-cabc-late-off-command = <0x39010000 0x351 0x1501 0x0 0x2550015 0x1000000 0x25320>;
				somc,mdss-dsi-cabc-enabled = <0x0>;
				qcom,mdss-dsi-h-sync-pulse = <0x1>;
				qcom,mdss-dsi-traffic-mode = "non_burst_sync_event";
				qcom,mdss-dsi-bllp-eof-power-mode;
				qcom,mdss-dsi-bllp-power-mode;
				qcom,mdss-dsi-lane-0-state;
				qcom,mdss-dsi-lane-1-state;
				qcom,mdss-dsi-lane-2-state;
				qcom,mdss-dsi-lane-3-state;
				qcom,mdss-dsi-panel-timings = <0xe6382600 0x686c2a3a 0x2c030400>;
				qcom,mdss-dsi-lp11-init;
				qcom,mdss-dsi-t-clk-post = <0x2>;
				qcom,mdss-dsi-t-clk-pre = <0x2b>;
				qcom,mdss-dsi-bl-min-level = <0x1>;
				qcom,mdss-dsi-bl-max-level = <0xff>;
				qcom,mdss-brightness-max-level = <0xff>;
				qcom,mdss-dsi-dma-trigger = "trigger_sw";
				qcom,mdss-dsi-mdp-trigger = "none";
				qcom,mdss-dsi-bl-pmic-control-type = "bl_ctrl_wled";
				qcom,mdss-dsi-pan-enable-dynamic-fps;
				qcom,mdss-dsi-pan-fps-update = "dfps_suspend_resume_mode";
				qcom,cont-splash-enabled;
				qcom,mdss-dsi-tx-eot-append;
				somc,driver-ic = <0x0>;
				somc,mul-channel-scaling = <0x3>;
				somc,mdss-phy-size-mm = <0x40 0x72>;
				somc,mdss-dsi-lane-config = [00 c2 ef 00 00 00 00 01 75 00 c2 ef 00 00 00 00 01 75 00 c2 ef 00 00 00 00 01 75 00 c2 ef 00 00 00 00 01 75 00 02 45 00 00 00 00 01 97];
				somc,mdss-dsi-disp-on-in-hs = <0x1>;
				somc,mdss-dsi-wait-time-before-on-cmd = <0x96>;
				somc,lcd-id = <0x0>;
				somc,lcd-id-adc = <0x0 0x7fffffff>;
				somc,disp-en-on-pre = <0x19>;
				somc,pw-on-rst-seq = <0x0 0x3c 0x1 0xa>;
				somc,disp-en-off-post = <0x32>;
				somc,pw-off-rst-b-seq = <0x0 0xa>;
				linux,phandle = <0x29>;
				phandle = <0x29>;
			};

			somc,default_panel_1 {
				qcom,mdss-dsi-panel-name = "default renesas video";
				qcom,mdss-dsi-panel-controller = <0x23>;
				qcom,mdss-dsi-panel-type = "dsi_video_mode";
				qcom,mdss-dsi-panel-destination = "display_1";
				qcom,mdss-dsi-panel-framerate = <0x3c>;
				qcom,mdss-dsi-virtual-channel-id = <0x0>;
				qcom,mdss-dsi-stream = <0x0>;
				qcom,mdss-dsi-panel-width = <0x438>;
				qcom,mdss-dsi-panel-height = <0x780>;
				qcom,mdss-dsi-h-front-porch = <0x80>;
				qcom,mdss-dsi-h-back-porch = <0x4c>;
				qcom,mdss-dsi-h-pulse-width = <0x4>;
				qcom,mdss-dsi-h-sync-skew = <0x0>;
				qcom,mdss-dsi-v-back-porch = <0x3>;
				qcom,mdss-dsi-v-front-porch = <0x4>;
				qcom,mdss-dsi-v-pulse-width = <0x2>;
				qcom,mdss-dsi-h-left-border = <0x0>;
				qcom,mdss-dsi-h-right-border = <0x0>;
				qcom,mdss-dsi-v-top-border = <0x0>;
				qcom,mdss-dsi-v-bottom-border = <0x0>;
				qcom,mdss-dsi-bpp = <0x18>;
				qcom,mdss-dsi-underflow-color = <0x0>;
				qcom,mdss-dsi-border-color = <0x0>;
				somc,mdss-dsi-init-command = <0x23010000 0x2b0 0x4230100 0x2 0x2301 0x0 0x2000023 0x1000000 0x2d601 0x29010000 0x3c0 0xf0f2901 0x0 0x3ec0010 0x29010000 0x19c7 0x519222b 0x38514150 0x5c646b74 0xf232b32 0x3f524455 0x61697077 0x29010000 0x19c8 0x318212b 0x3851424f 0x5d656c74 0xd222a32 0x3e524154 0x5d666d77 0x29010000 0x19c9 0x151e28 0x36504250 0x5e666d74 0xa1f272f 0x3d514155 0x5e676e77 0x5010000 0x111>;
				qcom,mdss-dsi-on-command = <0x5010000 0x129>;
				qcom,mdss-dsi-off-command = <0x5010000 0x14000128 0x5010000 0x6e000110>;
				qcom,mdss-dsi-on-command-state = "dsi_lp_mode";
				qcom,mdss-dsi-off-command-state = "dsi_hs_mode";
				somc,mdss-dsi-cabc-early-on-command = <0x39010000 0x351 0xfff1501 0x0 0x2532415 0x1000000 0x25502>;
				somc,mdss-dsi-cabc-late-off-command = <0x39010000 0x351 0x1501 0x0 0x2550015 0x1000000 0x25320>;
				somc,mdss-dsi-cabc-enabled = <0x0>;
				qcom,mdss-dsi-h-sync-pulse = <0x1>;
				qcom,mdss-dsi-traffic-mode = "non_burst_sync_event";
				qcom,mdss-dsi-bllp-eof-power-mode;
				qcom,mdss-dsi-bllp-power-mode;
				qcom,mdss-dsi-lane-0-state;
				qcom,mdss-dsi-lane-1-state;
				qcom,mdss-dsi-lane-2-state;
				qcom,mdss-dsi-lane-3-state;
				qcom,mdss-dsi-panel-timings = <0xe6382600 0x686c2a3a 0x2c030400>;
				qcom,mdss-dsi-lp11-init;
				qcom,mdss-dsi-t-clk-post = <0x2>;
				qcom,mdss-dsi-t-clk-pre = <0x2b>;
				qcom,mdss-dsi-bl-min-level = <0x1>;
				qcom,mdss-dsi-bl-max-level = <0xff>;
				qcom,mdss-brightness-max-level = <0xff>;
				qcom,mdss-dsi-dma-trigger = "trigger_sw";
				qcom,mdss-dsi-mdp-trigger = "none";
				qcom,mdss-dsi-bl-pmic-control-type = "bl_ctrl_wled";
				qcom,mdss-dsi-pan-enable-dynamic-fps;
				qcom,mdss-dsi-pan-fps-update = "dfps_suspend_resume_mode";
				qcom,cont-splash-enabled;
				qcom,mdss-dsi-tx-eot-append;
				somc,driver-ic = <0x0>;
				somc,mul-channel-scaling = <0x3>;
				somc,mdss-phy-size-mm = <0x40 0x72>;
				somc,mdss-dsi-lane-config = [00 c2 ef 00 00 00 00 01 75 00 c2 ef 00 00 00 00 01 75 00 c2 ef 00 00 00 00 01 75 00 c2 ef 00 00 00 00 01 75 00 02 45 00 00 00 00 01 97];
				somc,mdss-dsi-disp-on-in-hs = <0x1>;
				somc,mdss-dsi-wait-time-before-on-cmd = <0x96>;
				somc,lcd-id = <0x1>;
				somc,lcd-id-adc = <0x0 0x7fffffff>;
				somc,disp-en-on-pre = <0x19>;
				somc,pw-on-rst-seq = <0x0 0x3c 0x1 0xa>;
				somc,disp-en-off-post = <0x32>;
				somc,pw-off-rst-b-seq = <0x0 0xa>;
			};
		};

		qcom,mdss_dsi@fd922800 {
			compatible = "qcom,mdss-dsi-ctrl";
			label = "MDSS DSI CTRL->0";
			cell-index = <0x0>;
			reg = <0xfd922800 0x1f8 0xfd922b00 0x2b0 0xfdf30000 0x108>;
			reg-names = "dsi_ctrl", "dsi_phy", "mmss_misc_phys";
			vdd-supply = <0x24>;
			vddio-supply = <0x2>;
			vdda-supply = <0x25>;
			qcom,mdss-fb-map = <0x26>;
			qcom,mdss-mdp = <0x27>;
			qcom,platform-reset-gpio = <0x28 0x13 0x0>;
			qcom,platform-enable-gpio = <0x28 0x14 0x0>;
			qcom,platform-strength-ctrl = [ff 06];
			qcom,platform-bist-ctrl = [00 00 b1 ff 00 00];
			qcom,platform-regulator-settings = [07 09 03 00 20 00 01];
			qcom,platform-lane-config;
			qcom,dsi-pref-prim-pan = <0x29>;
			linux,phandle = <0x23>;
			phandle = <0x23>;

			qcom,platform-supply-entry1 {
				qcom,supply-name = "vdd";
				qcom,supply-min-voltage = <0x0>;
				qcom,supply-max-voltage = <0x0>;
				qcom,supply-enable-load = <0x186a0>;
				qcom,supply-disable-load = <0x64>;
				qcom,supply-pre-on-sleep = <0x0>;
				qcom,supply-post-on-sleep = <0x0>;
				qcom,supply-pre-off-sleep = <0x0>;
				qcom,supply-post-off-sleep = <0x0>;
			};

			qcom,platform-supply-entry2 {
				qcom,supply-name = "vddio";
				qcom,supply-min-voltage = <0x1b7740>;
				qcom,supply-max-voltage = <0x1b7740>;
				qcom,supply-enable-load = <0x186a0>;
				qcom,supply-disable-load = <0x64>;
				qcom,supply-pre-on-sleep = <0x0>;
				qcom,supply-post-on-sleep = <0x0>;
				qcom,supply-pre-off-sleep = <0x0>;
				qcom,supply-post-off-sleep = <0x0>;
			};

			qcom,platform-supply-entry3 {
				qcom,supply-name = "vdda";
				qcom,supply-min-voltage = <0x124f80>;
				qcom,supply-max-voltage = <0x124f80>;
				qcom,supply-enable-load = <0x186a0>;
				qcom,supply-disable-load = <0x64>;
				qcom,supply-pre-on-sleep = <0x0>;
				qcom,supply-post-on-sleep = <0x0>;
				qcom,supply-pre-off-sleep = <0x0>;
				qcom,supply-post-off-sleep = <0x0>;
			};
		};

		qcom,mdss_dsi@fd922e00 {
			compatible = "qcom,mdss-dsi-ctrl";
			label = "MDSS DSI CTRL->1";
			cell-index = <0x1>;
			reg = <0xfd922e00 0x1f8 0xfd923100 0x2b0 0xfdf30000 0x108>;
			reg-names = "dsi_ctrl", "dsi_phy", "mmss_misc_phys";
			vdd-supply = <0x2a>;
			vddio-supply = <0x2>;
			vdda-supply = <0x25>;
			qcom,mdss-fb-map = <0x26>;
			qcom,mdss-mdp = <0x27>;
			qcom,platform-strength-ctrl = [ff 06];
			qcom,platform-bist-ctrl = [00 00 b1 ff 00 00];
			qcom,platform-regulator-settings = [07 09 03 00 20 00 01];
			qcom,platform-lane-config = [00 00 00 00 00 00 00 01 97 00 00 00 00 00 00 00 01 97 00 00 00 00 00 00 00 01 97 00 00 00 00 00 00 00 01 97 00 c0 00 00 00 00 00 01 bb];
			linux,phandle = <0x22>;
			phandle = <0x22>;

			qcom,platform-supply-entry1 {
				qcom,supply-name = "vdd";
				qcom,supply-min-voltage = <0x2dc6c0>;
				qcom,supply-max-voltage = <0x2dc6c0>;
				qcom,supply-enable-load = <0x186a0>;
				qcom,supply-disable-load = <0x64>;
				qcom,supply-pre-on-sleep = <0x0>;
				qcom,supply-post-on-sleep = <0x14>;
				qcom,supply-pre-off-sleep = <0x0>;
				qcom,supply-post-off-sleep = <0x0>;
			};

			qcom,platform-supply-entry2 {
				qcom,supply-name = "vddio";
				qcom,supply-min-voltage = <0x1b7740>;
				qcom,supply-max-voltage = <0x1b7740>;
				qcom,supply-enable-load = <0x186a0>;
				qcom,supply-disable-load = <0x64>;
				qcom,supply-pre-on-sleep = <0x0>;
				qcom,supply-post-on-sleep = <0x14>;
				qcom,supply-pre-off-sleep = <0x0>;
				qcom,supply-post-off-sleep = <0x0>;
			};

			qcom,platform-supply-entry3 {
				qcom,supply-name = "vdda";
				qcom,supply-min-voltage = <0x124f80>;
				qcom,supply-max-voltage = <0x124f80>;
				qcom,supply-enable-load = <0x186a0>;
				qcom,supply-disable-load = <0x64>;
				qcom,supply-pre-on-sleep = <0x0>;
				qcom,supply-post-on-sleep = <0x0>;
				qcom,supply-pre-off-sleep = <0x0>;
				qcom,supply-post-off-sleep = <0x0>;
			};
		};

		qcom,hdmi_tx@fd922100 {
			cell-index = <0x0>;
			compatible = "qcom,hdmi-tx";
			reg = <0xfd922100 0x370 0xfd922500 0x7c 0xfc4b8000 0x60f0>;
			reg-names = "core_physical", "phy_physical", "qfprom_physical";
			hpd-gdsc-supply = <0x1e>;
			hpd-5v-supply = <0x2b>;
			core-vdda-supply = <0x2>;
			core-vcc-supply = <0x2c>;
			qcom,hdmi-tx-supply-names = "hpd-gdsc", "core-vdda", "core-vcc";
			qcom,hdmi-tx-min-voltage-level = <0x0 0x1b7740 0x1b7740>;
			qcom,hdmi-tx-max-voltage-level = <0x0 0x1b7740 0x1b7740>;
			qcom,hdmi-tx-peak-current = <0x0 0x493e0 0x0>;
			qcom,hdmi-tx-ddc-clk = <0x5 0x20 0x0>;
			qcom,hdmi-tx-ddc-data = <0x5 0x21 0x0>;
			qcom,hdmi-tx-hpd = <0x5 0x22 0x0>;
			qcom,mdss-fb-map = <0x2d>;
			status = "ok";
			linux,phandle = <0x54>;
			phandle = <0x54>;

			qcom,msm-hdmi-audio-rx {
				compatible = "qcom,msm-hdmi-audio-codec-rx";
			};
		};

		qcom,mdss_wb_panel {
			compatible = "qcom,mdss_wb";
			qcom,mdss_pan_res = <0x780 0x438>;
			qcom,mdss_pan_bpp = <0x18>;
			qcom,mdss-fb-map = <0x2e>;
		};

		qcom,mdss_edp@fd923400 {
			compatible = "qcom,mdss-edp";
			reg = <0xfd923400 0x700 0xfd8c2000 0x1000>;
			reg-names = "edp_base", "mmss_cc_base";
			vdda-supply = <0x2>;
			gpio-panel-en = <0x5 0x3a 0x0>;
			qcom,mdss-fb-map = <0x26>;
			gpio-panel-hpd = <0x5 0x66 0x0>;
		};

		qcom,spmi@fc4c0000 {
			cell-index = <0x0>;
			compatible = "qcom,spmi-pmic-arb";
			reg-names = "core", "intr", "cnfg";
			reg = <0xfc4cf000 0x1000 0xfc4cb000 0x1000 0xfc4ca000 0x1000>;
			interrupts = <0x0 0xbe 0x0 0x0 0xbb 0x0>;
			qcom,pmic-arb-ee = <0x0>;
			qcom,pmic-arb-channel = <0x0>;
			#address-cells = <0x1>;
			#size-cells = <0x0>;
			interrupt-controller;
			#interrupt-cells = <0x3>;
			linux,phandle = <0x60>;
			phandle = <0x60>;

			qcom,pm8941@0 {
				reg = <0x0>;
				spmi-slave-container;
				#address-cells = <0x1>;
				#size-cells = <0x1>;


				gpios {
					spmi-dev-container;
					compatible = "qcom,qpnp-pin";
					gpio-controller;
					#gpio-cells = <0x2>;
					#address-cells = <0x1>;
					#size-cells = <0x1>;
					label = "pm8941-gpio";
					linux,phandle = <0x28>;
					phandle = <0x28>;

					gpio@cb00 {
						reg = <0xcb00 0x100>;
						qcom,pin-num = <0xc>;
						qcom,mode = <0x0>;
						qcom,out-strength = <0x1>;
						qcom,src-sel = <0x0>;
						qcom,master-en = <0x1>;
						qcom,vin-sel = <0x2>;
						qcom,pull = <0x4>;
						status = "ok";
					};

					gpio@d200 {
						reg = <0xd200 0x100>;
						qcom,pin-num = <0x13>;
						qcom,mode = <0x1>;
						qcom,output-type = <0x0>;
						qcom,pull = <0x5>;
						qcom,vin-sel = <0x2>;
						qcom,out-strength = <0x1>;
						qcom,src-sel = <0x0>;
						qcom,master-en = <0x1>;
						qcom,invert = <0x0>;
						somc,keep_high_at_init;
						status = "ok";
					};

					gpio@d300 {
						reg = <0xd300 0x100>;
						qcom,pin-num = <0x14>;
						qcom,mode = <0x1>;
						qcom,out-strength = <0x1>;
						qcom,src-sel = <0x0>;
						qcom,master-en = <0x1>;
						status = "ok";
						qcom,output-type = <0x0>;
						qcom,vin-sel = <0x2>;
						qcom,invert = <0x0>;
						somc,keep_high_at_init;
					};

					gpio@d900 {
						reg = <0xd900 0x100>;
						qcom,pin-num = <0x1a>;
						qcom,mode = <0x1>;
						qcom,out-strength = <0x1>;
						qcom,src-sel = <0x2>;
						qcom,master-en = <0x0>;
						status = "ok";
					};
				};
			};
			qcom,pm8941@1 {
				reg = <0x1>;
				spmi-slave-container;
				#address-cells = <0x1>;
				#size-cells = <0x1>;
				qcom,leds@d800 {
					compatible = "qcom,leds-qpnp";
					reg = <0xd800 0x100>;
					label = "wled";
					status = "okay";

					qcom,wled_0 {
						label = "wled";
						linux,name = "wled:backlight";
						linux,default-trigger = "bkl-trigger";
						qcom,cs-out-en = <0x1>;
						qcom,op-fdbck = <0x0>;
						qcom,default-state = "on";
						qcom,max-current = <0x14>;
						qcom,ctrl-delay-us = <0x0>;
						qcom,boost-curr-lim = <0x3>;
						qcom,cp-sel = <0x0>;
						qcom,switch-freq = <0x2>;
						qcom,ovp-val = <0x2>;
						qcom,num-strings = <0x2>;
						qcom,id = <0x0>;
						qcom,cabc-en = <0x0>;
					};
				};

			};
		};
};
